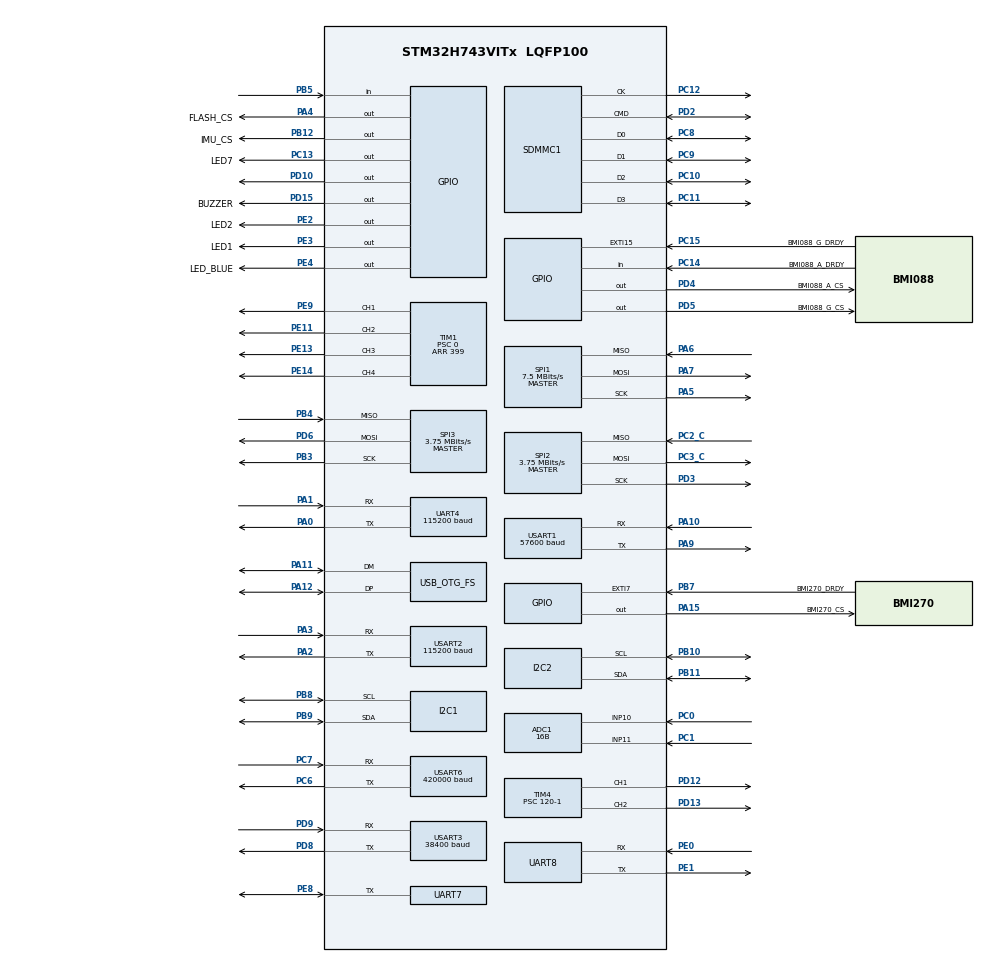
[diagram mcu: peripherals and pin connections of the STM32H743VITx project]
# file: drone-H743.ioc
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ADC1.Channel-0\#ChannelRegularConversion=ADC_CHANNEL_11
ADC1.Channel-1\#ChannelRegularConversion=ADC_CHANNEL_10
ADC1.ClockPrescaler=ADC_CLOCK_ASYNC_DIV4
ADC1.ContinuousConvMode=DISABLE
ADC1.ConversionDataManagement=ADC_CONVERSIONDATA_DR
ADC1.DiscontinuousConvMode=ENABLE
ADC1.EOCSelection=ADC_EOC_SINGLE_CONV
ADC1.ExternalTrigConv=ADC_SOFTWARE_START
ADC1.ExternalTrigConvEdge=ADC_EXTERNALTRIGCONVEDGE_NONE
ADC1.NbrOfConversion=2
ADC1.NbrOfConversionFlag=1
ADC1.NbrOfDiscConversion=1
ADC1.OffsetNumber-0\#ChannelRegularConversion=ADC_OFFSET_NONE
ADC1.OffsetNumber-1\#ChannelRegularConversion=ADC_OFFSET_NONE
ADC1.OffsetSignedSaturation-0\#ChannelRegularConversion=DISABLE
ADC1.OffsetSignedSaturation-1\#ChannelRegularConversion=DISABLE
ADC1.Overrun=ADC_OVR_DATA_PRESERVED
ADC1.Rank-0\#ChannelRegularConversion=1
ADC1.Rank-1\#ChannelRegularConversion=2
ADC1.Resolution=ADC_RESOLUTION_16B
ADC1.SamplingTime-0\#ChannelRegularConversion=ADC_SAMPLETIME_387CYCLES_5
ADC1.SamplingTime-1\#ChannelRegularConversion=ADC_SAMPLETIME_387CYCLES_5
ADC1.ScanConvMode=ADC_SCAN_ENABLE
ADC1.master=1
CORTEX_M7.CPU_DCache=Enabled
CORTEX_M7.CPU_ICache=Enabled
CORTEX_M7.default_mode_Activation=1
Dma.Request0=USART1_RX
Dma.Request1=USART1_TX
Dma.Request10=USART6_RX
Dma.Request11=USART6_TX
Dma.Request12=UART7_TX
Dma.Request13=UART7_RX
Dma.Request14=USART3_RX
Dma.Request15=USART3_TX
Dma.Request2=TIM1_UP
Dma.Request3=UART8_TX
Dma.Request4=UART4_RX
Dma.Request5=UART4_TX
Dma.Request6=SPI2_RX
Dma.Request7=SPI2_TX
Dma.Request8=SPI1_RX
Dma.Request9=SPI1_TX
Dma.SPI1_RX.8.Direction=DMA_PERIPH_TO_MEMORY
Dma.SPI1_RX.8.EventEnable=DISABLE
Dma.SPI1_RX.8.FIFOMode=DMA_FIFOMODE_DISABLE
Dma.SPI1_RX.8.Instance=DMA2_Stream0
Dma.SPI1_RX.8.MemDataAlignment=DMA_MDATAALIGN_BYTE
Dma.SPI1_RX.8.MemInc=DMA_MINC_ENABLE
Dma.SPI1_RX.8.Mode=DMA_NORMAL
Dma.SPI1_RX.8.PeriphDataAlignment=DMA_PDATAALIGN_BYTE
Dma.SPI1_RX.8.PeriphInc=DMA_PINC_DISABLE
Dma.SPI1_RX.8.Polarity=HAL_DMAMUX_REQ_GEN_RISING
Dma.SPI1_RX.8.Priority=DMA_PRIORITY_HIGH
Dma.SPI1_RX.8.RequestNumber=1
Dma.SPI1_RX.8.SignalID=NONE
Dma.SPI1_RX.8.SyncEnable=DISABLE
Dma.SPI1_RX.8.SyncPolarity=HAL_DMAMUX_SYNC_NO_EVENT
Dma.SPI1_RX.8.SyncRequestNumber=1
Dma.SPI1_RX.8.SyncSignalID=NONE
Dma.SPI1_TX.9.Direction=DMA_MEMORY_TO_PERIPH
Dma.SPI1_TX.9.EventEnable=DISABLE
Dma.SPI1_TX.9.FIFOMode=DMA_FIFOMODE_DISABLE
Dma.SPI1_TX.9.Instance=DMA2_Stream1
Dma.SPI1_TX.9.MemDataAlignment=DMA_MDATAALIGN_BYTE
Dma.SPI1_TX.9.MemInc=DMA_MINC_ENABLE
Dma.SPI1_TX.9.Mode=DMA_NORMAL
Dma.SPI1_TX.9.PeriphDataAlignment=DMA_PDATAALIGN_BYTE
Dma.SPI1_TX.9.PeriphInc=DMA_PINC_DISABLE
Dma.SPI1_TX.9.Polarity=HAL_DMAMUX_REQ_GEN_RISING
Dma.SPI1_TX.9.Priority=DMA_PRIORITY_HIGH
Dma.SPI1_TX.9.RequestNumber=1
Dma.SPI1_TX.9.SignalID=NONE
Dma.SPI1_TX.9.SyncEnable=DISABLE
Dma.SPI1_TX.9.SyncPolarity=HAL_DMAMUX_SYNC_NO_EVENT
Dma.SPI1_TX.9.SyncRequestNumber=1
Dma.SPI1_TX.9.SyncSignalID=NONE
Dma.SPI2_RX.6.Direction=DMA_PERIPH_TO_MEMORY
Dma.SPI2_RX.6.EventEnable=DISABLE
Dma.SPI2_RX.6.FIFOMode=DMA_FIFOMODE_DISABLE
Dma.SPI2_RX.6.Instance=DMA1_Stream6
Dma.SPI2_RX.6.MemDataAlignment=DMA_MDATAALIGN_BYTE
Dma.SPI2_RX.6.MemInc=DMA_MINC_ENABLE
Dma.SPI2_RX.6.Mode=DMA_NORMAL
Dma.SPI2_RX.6.PeriphDataAlignment=DMA_PDATAALIGN_BYTE
Dma.SPI2_RX.6.PeriphInc=DMA_PINC_DISABLE
Dma.SPI2_RX.6.Polarity=HAL_DMAMUX_REQ_GEN_RISING
Dma.SPI2_RX.6.Priority=DMA_PRIORITY_VERY_HIGH
Dma.SPI2_RX.6.RequestNumber=1
Dma.SPI2_RX.6.SignalID=NONE
Dma.SPI2_RX.6.SyncEnable=DISABLE
Dma.SPI2_RX.6.SyncPolarity=HAL_DMAMUX_SYNC_NO_EVENT
Dma.SPI2_RX.6.SyncRequestNumber=1
Dma.SPI2_RX.6.SyncSignalID=NONE
Dma.SPI2_TX.7.Direction=DMA_MEMORY_TO_PERIPH
Dma.SPI2_TX.7.EventEnable=DISABLE
Dma.SPI2_TX.7.FIFOMode=DMA_FIFOMODE_DISABLE
Dma.SPI2_TX.7.Instance=DMA1_Stream7
Dma.SPI2_TX.7.MemDataAlignment=DMA_MDATAALIGN_BYTE
Dma.SPI2_TX.7.MemInc=DMA_MINC_ENABLE
Dma.SPI2_TX.7.Mode=DMA_NORMAL
Dma.SPI2_TX.7.PeriphDataAlignment=DMA_PDATAALIGN_BYTE
Dma.SPI2_TX.7.PeriphInc=DMA_PINC_DISABLE
Dma.SPI2_TX.7.Polarity=HAL_DMAMUX_REQ_GEN_RISING
Dma.SPI2_TX.7.Priority=DMA_PRIORITY_VERY_HIGH
Dma.SPI2_TX.7.RequestNumber=1
Dma.SPI2_TX.7.SignalID=NONE
Dma.SPI2_TX.7.SyncEnable=DISABLE
Dma.SPI2_TX.7.SyncPolarity=HAL_DMAMUX_SYNC_NO_EVENT
Dma.SPI2_TX.7.SyncRequestNumber=1
Dma.SPI2_TX.7.SyncSignalID=NONE
Dma.TIM1_UP.2.Direction=DMA_MEMORY_TO_PERIPH
Dma.TIM1_UP.2.EventEnable=DISABLE
Dma.TIM1_UP.2.FIFOMode=DMA_FIFOMODE_DISABLE
Dma.TIM1_UP.2.Instance=DMA1_Stream2
Dma.TIM1_UP.2.MemDataAlignment=DMA_MDATAALIGN_WORD
Dma.TIM1_UP.2.MemInc=DMA_MINC_ENABLE
Dma.TIM1_UP.2.Mode=DMA_NORMAL
Dma.TIM1_UP.2.PeriphDataAlignment=DMA_PDATAALIGN_WORD
Dma.TIM1_UP.2.PeriphInc=DMA_PINC_DISABLE
Dma.TIM1_UP.2.Polarity=HAL_DMAMUX_REQ_GEN_RISING
Dma.TIM1_UP.2.Priority=DMA_PRIORITY_HIGH
Dma.TIM1_UP.2.RequestNumber=1
Dma.TIM1_UP.2.SignalID=NONE
Dma.TIM1_UP.2.SyncEnable=DISABLE
Dma.TIM1_UP.2.SyncPolarity=HAL_DMAMUX_SYNC_NO_EVENT
Dma.TIM1_UP.2.SyncRequestNumber=1
Dma.TIM1_UP.2.SyncSignalID=NONE
Dma.UART4_RX.4.Direction=DMA_PERIPH_TO_MEMORY
Dma.UART4_RX.4.EventEnable=DISABLE
Dma.UART4_RX.4.FIFOMode=DMA_FIFOMODE_DISABLE
Dma.UART4_RX.4.Instance=DMA1_Stream4
Dma.UART4_RX.4.MemDataAlignment=DMA_MDATAALIGN_BYTE
Dma.UART4_RX.4.MemInc=DMA_MINC_ENABLE
Dma.UART4_RX.4.Mode=DMA_CIRCULAR
Dma.UART4_RX.4.PeriphDataAlignment=DMA_PDATAALIGN_BYTE
Dma.UART4_RX.4.PeriphInc=DMA_PINC_DISABLE
Dma.UART4_RX.4.Polarity=HAL_DMAMUX_REQ_GEN_RISING
Dma.UART4_RX.4.Priority=DMA_PRIORITY_HIGH
Dma.UART4_RX.4.RequestNumber=1
Dma.UART4_RX.4.SignalID=NONE
Dma.UART4_RX.4.SyncEnable=DISABLE
Dma.UART4_RX.4.SyncPolarity=HAL_DMAMUX_SYNC_NO_EVENT
Dma.UART4_RX.4.SyncRequestNumber=1
Dma.UART4_RX.4.SyncSignalID=NONE
Dma.UART4_TX.5.Direction=DMA_MEMORY_TO_PERIPH
Dma.UART4_TX.5.EventEnable=DISABLE
Dma.UART4_TX.5.FIFOMode=DMA_FIFOMODE_DISABLE
Dma.UART4_TX.5.Instance=DMA1_Stream5
Dma.UART4_TX.5.MemDataAlignment=DMA_MDATAALIGN_BYTE
Dma.UART4_TX.5.MemInc=DMA_MINC_ENABLE
Dma.UART4_TX.5.Mode=DMA_NORMAL
Dma.UART4_TX.5.PeriphDataAlignment=DMA_PDATAALIGN_BYTE
Dma.UART4_TX.5.PeriphInc=DMA_PINC_DISABLE
Dma.UART4_TX.5.Polarity=HAL_DMAMUX_REQ_GEN_RISING
Dma.UART4_TX.5.Priority=DMA_PRIORITY_HIGH
Dma.UART4_TX.5.RequestNumber=1
Dma.UART4_TX.5.SignalID=NONE
Dma.UART4_TX.5.SyncEnable=DISABLE
Dma.UART4_TX.5.SyncPolarity=HAL_DMAMUX_SYNC_NO_EVENT
Dma.UART4_TX.5.SyncRequestNumber=1
Dma.UART4_TX.5.SyncSignalID=NONE
Dma.UART7_RX.13.Direction=DMA_PERIPH_TO_MEMORY
Dma.UART7_RX.13.EventEnable=DISABLE
Dma.UART7_RX.13.FIFOMode=DMA_FIFOMODE_DISABLE
Dma.UART7_RX.13.Instance=DMA2_Stream5
Dma.UART7_RX.13.MemDataAlignment=DMA_MDATAALIGN_BYTE
Dma.UART7_RX.13.MemInc=DMA_MINC_ENABLE
Dma.UART7_RX.13.Mode=DMA_NORMAL
Dma.UART7_RX.13.PeriphDataAlignment=DMA_PDATAALIGN_BYTE
Dma.UART7_RX.13.PeriphInc=DMA_PINC_DISABLE
Dma.UART7_RX.13.Polarity=HAL_DMAMUX_REQ_GEN_RISING
Dma.UART7_RX.13.Priority=DMA_PRIORITY_VERY_HIGH
Dma.UART7_RX.13.RequestNumber=1
Dma.UART7_RX.13.SignalID=NONE
Dma.UART7_RX.13.SyncEnable=DISABLE
Dma.UART7_RX.13.SyncPolarity=HAL_DMAMUX_SYNC_NO_EVENT
Dma.UART7_RX.13.SyncRequestNumber=1
Dma.UART7_RX.13.SyncSignalID=NONE
Dma.UART7_TX.12.Direction=DMA_MEMORY_TO_PERIPH
Dma.UART7_TX.12.EventEnable=DISABLE
Dma.UART7_TX.12.FIFOMode=DMA_FIFOMODE_DISABLE
Dma.UART7_TX.12.Instance=DMA2_Stream4
Dma.UART7_TX.12.MemDataAlignment=DMA_MDATAALIGN_BYTE
Dma.UART7_TX.12.MemInc=DMA_MINC_ENABLE
Dma.UART7_TX.12.Mode=DMA_NORMAL
Dma.UART7_TX.12.PeriphDataAlignment=DMA_PDATAALIGN_BYTE
Dma.UART7_TX.12.PeriphInc=DMA_PINC_DISABLE
Dma.UART7_TX.12.Polarity=HAL_DMAMUX_REQ_GEN_RISING
Dma.UART7_TX.12.Priority=DMA_PRIORITY_VERY_HIGH
Dma.UART7_TX.12.RequestNumber=1
Dma.UART7_TX.12.SignalID=NONE
Dma.UART7_TX.12.SyncEnable=DISABLE
Dma.UART7_TX.12.SyncPolarity=HAL_DMAMUX_SYNC_NO_EVENT
Dma.UART7_TX.12.SyncRequestNumber=1
Dma.UART7_TX.12.SyncSignalID=NONE
Dma.UART8_TX.3.Direction=DMA_MEMORY_TO_PERIPH
Dma.UART8_TX.3.EventEnable=DISABLE
Dma.UART8_TX.3.FIFOMode=DMA_FIFOMODE_DISABLE
Dma.UART8_TX.3.Instance=DMA1_Stream3
Dma.UART8_TX.3.MemDataAlignment=DMA_MDATAALIGN_BYTE
Dma.UART8_TX.3.MemInc=DMA_MINC_ENABLE
Dma.UART8_TX.3.Mode=DMA_NORMAL
Dma.UART8_TX.3.PeriphDataAlignment=DMA_PDATAALIGN_BYTE
Dma.UART8_TX.3.PeriphInc=DMA_PINC_DISABLE
Dma.UART8_TX.3.Polarity=HAL_DMAMUX_REQ_GEN_RISING
Dma.UART8_TX.3.Priority=DMA_PRIORITY_LOW
Dma.UART8_TX.3.RequestNumber=1
Dma.UART8_TX.3.SignalID=NONE
Dma.UART8_TX.3.SyncEnable=DISABLE
Dma.UART8_TX.3.SyncPolarity=HAL_DMAMUX_SYNC_NO_EVENT
Dma.UART8_TX.3.SyncRequestNumber=1
Dma.UART8_TX.3.SyncSignalID=NONE
Dma.USART1_RX.0.Direction=DMA_PERIPH_TO_MEMORY
Dma.USART1_RX.0.EventEnable=DISABLE
Dma.USART1_RX.0.FIFOMode=DMA_FIFOMODE_DISABLE
Dma.USART1_RX.0.Instance=DMA1_Stream0
Dma.USART1_RX.0.MemDataAlignment=DMA_MDATAALIGN_BYTE
Dma.USART1_RX.0.MemInc=DMA_MINC_ENABLE
Dma.USART1_RX.0.Mode=DMA_CIRCULAR
Dma.USART1_RX.0.PeriphDataAlignment=DMA_PDATAALIGN_BYTE
Dma.USART1_RX.0.PeriphInc=DMA_PINC_DISABLE
Dma.USART1_RX.0.Polarity=HAL_DMAMUX_REQ_GEN_RISING
Dma.USART1_RX.0.Priority=DMA_PRIORITY_LOW
Dma.USART1_RX.0.RequestNumber=1
Dma.USART1_RX.0.SignalID=NONE
Dma.USART1_RX.0.SyncEnable=DISABLE
Dma.USART1_RX.0.SyncPolarity=HAL_DMAMUX_SYNC_NO_EVENT
Dma.USART1_RX.0.SyncRequestNumber=1
Dma.USART1_RX.0.SyncSignalID=NONE
Dma.USART1_TX.1.Direction=DMA_MEMORY_TO_PERIPH
Dma.USART1_TX.1.EventEnable=DISABLE
Dma.USART1_TX.1.FIFOMode=DMA_FIFOMODE_DISABLE
Dma.USART1_TX.1.Instance=DMA1_Stream1
Dma.USART1_TX.1.MemDataAlignment=DMA_MDATAALIGN_BYTE
Dma.USART1_TX.1.MemInc=DMA_MINC_ENABLE
Dma.USART1_TX.1.Mode=DMA_NORMAL
Dma.USART1_TX.1.PeriphDataAlignment=DMA_PDATAALIGN_BYTE
Dma.USART1_TX.1.PeriphInc=DMA_PINC_DISABLE
Dma.USART1_TX.1.Polarity=HAL_DMAMUX_REQ_GEN_RISING
Dma.USART1_TX.1.Priority=DMA_PRIORITY_LOW
Dma.USART1_TX.1.RequestNumber=1
Dma.USART1_TX.1.SignalID=NONE
Dma.USART1_TX.1.SyncEnable=DISABLE
Dma.USART1_TX.1.SyncPolarity=HAL_DMAMUX_SYNC_NO_EVENT
Dma.USART1_TX.1.SyncRequestNumber=1
Dma.USART1_TX.1.SyncSignalID=NONE
Dma.USART3_RX.14.Direction=DMA_PERIPH_TO_MEMORY
Dma.USART3_RX.14.EventEnable=DISABLE
Dma.USART3_RX.14.FIFOMode=DMA_FIFOMODE_DISABLE
Dma.USART3_RX.14.Instance=DMA2_Stream6
Dma.USART3_RX.14.MemDataAlignment=DMA_MDATAALIGN_BYTE
Dma.USART3_RX.14.MemInc=DMA_MINC_ENABLE
Dma.USART3_RX.14.Mode=DMA_CIRCULAR
Dma.USART3_RX.14.PeriphDataAlignment=DMA_PDATAALIGN_BYTE
Dma.USART3_RX.14.PeriphInc=DMA_PINC_DISABLE
Dma.USART3_RX.14.Polarity=HAL_DMAMUX_REQ_GEN_RISING
Dma.USART3_RX.14.Priority=DMA_PRIORITY_HIGH
Dma.USART3_RX.14.RequestNumber=1
Dma.USART3_RX.14.SignalID=NONE
Dma.USART3_RX.14.SyncEnable=DISABLE
Dma.USART3_RX.14.SyncPolarity=HAL_DMAMUX_SYNC_NO_EVENT
Dma.USART3_RX.14.SyncRequestNumber=1
Dma.USART3_RX.14.SyncSignalID=NONE
Dma.USART3_TX.15.Direction=DMA_MEMORY_TO_PERIPH
Dma.USART3_TX.15.EventEnable=DISABLE
Dma.USART3_TX.15.FIFOMode=DMA_FIFOMODE_DISABLE
Dma.USART3_TX.15.Instance=DMA2_Stream7
Dma.USART3_TX.15.MemDataAlignment=DMA_MDATAALIGN_BYTE
Dma.USART3_TX.15.MemInc=DMA_MINC_ENABLE
Dma.USART3_TX.15.Mode=DMA_NORMAL
Dma.USART3_TX.15.PeriphDataAlignment=DMA_PDATAALIGN_BYTE
Dma.USART3_TX.15.PeriphInc=DMA_PINC_DISABLE
Dma.USART3_TX.15.Polarity=HAL_DMAMUX_REQ_GEN_RISING
Dma.USART3_TX.15.Priority=DMA_PRIORITY_HIGH
Dma.USART3_TX.15.RequestNumber=1
Dma.USART3_TX.15.SignalID=NONE
Dma.USART3_TX.15.SyncEnable=DISABLE
Dma.USART3_TX.15.SyncPolarity=HAL_DMAMUX_SYNC_NO_EVENT
Dma.USART3_TX.15.SyncRequestNumber=1
Dma.USART3_TX.15.SyncSignalID=NONE
Dma.USART6_RX.10.Direction=DMA_PERIPH_TO_MEMORY
Dma.USART6_RX.10.EventEnable=DISABLE
Dma.USART6_RX.10.FIFOMode=DMA_FIFOMODE_DISABLE
Dma.USART6_RX.10.Instance=DMA2_Stream2
Dma.USART6_RX.10.MemDataAlignment=DMA_MDATAALIGN_BYTE
Dma.USART6_RX.10.MemInc=DMA_MINC_ENABLE
Dma.USART6_RX.10.Mode=DMA_CIRCULAR
Dma.USART6_RX.10.PeriphDataAlignment=DMA_PDATAALIGN_BYTE
Dma.USART6_RX.10.PeriphInc=DMA_PINC_DISABLE
Dma.USART6_RX.10.Polarity=HAL_DMAMUX_REQ_GEN_RISING
Dma.USART6_RX.10.Priority=DMA_PRIORITY_LOW
Dma.USART6_RX.10.RequestNumber=1
Dma.USART6_RX.10.SignalID=NONE
Dma.USART6_RX.10.SyncEnable=DISABLE
Dma.USART6_RX.10.SyncPolarity=HAL_DMAMUX_SYNC_NO_EVENT
Dma.USART6_RX.10.SyncRequestNumber=1
Dma.USART6_RX.10.SyncSignalID=NONE
Dma.USART6_TX.11.Direction=DMA_MEMORY_TO_PERIPH
Dma.USART6_TX.11.EventEnable=DISABLE
Dma.USART6_TX.11.FIFOMode=DMA_FIFOMODE_DISABLE
Dma.USART6_TX.11.Instance=DMA2_Stream3
Dma.USART6_TX.11.MemDataAlignment=DMA_MDATAALIGN_BYTE
Dma.USART6_TX.11.MemInc=DMA_MINC_ENABLE
Dma.USART6_TX.11.Mode=DMA_NORMAL
Dma.USART6_TX.11.PeriphDataAlignment=DMA_PDATAALIGN_BYTE
Dma.USART6_TX.11.PeriphInc=DMA_PINC_DISABLE
Dma.USART6_TX.11.Polarity=HAL_DMAMUX_REQ_GEN_RISING
Dma.USART6_TX.11.Priority=DMA_PRIORITY_LOW
Dma.USART6_TX.11.RequestNumber=1
Dma.USART6_TX.11.SignalID=NONE
Dma.USART6_TX.11.SyncEnable=DISABLE
Dma.USART6_TX.11.SyncPolarity=HAL_DMAMUX_SYNC_NO_EVENT
Dma.USART6_TX.11.SyncRequestNumber=1
Dma.USART6_TX.11.SyncSignalID=NONE
FREERTOS.Queues01=uartTxQueue,32,APP_UART_TxMessage,0,Dynamic,NULL,NULL;SensorSampleQueue,8,APP_Sensor_SampleMessage,0,Dynamic,NULL,NULL;backgroundReqQueue,8,APP_BackgroundRequest,0,Dynamic,NULL,NULL;backgroundRespQueue,8,APP_BackgroundResponse,0,Dynamic,NULL,NULL;vofaLogQueue,1,APP_Sensor_SampleMessage,0,Dynamic,NULL,NULL
FREERTOS.RecursiveMutexes01=flashBusMutex,Dynamic,NULL
FREERTOS.Tasks01=Stabilizer,24,2048,StabilizerTask,Default,NULL,Dynamic,NULL,NULL;SensorTask,24,512,Sensor_Task,Default,NULL,Dynamic,NULL,NULL;messageTask,16,1024,message_push,Default,NULL,Dynamic,NULL,NULL;UARTTask,24,1024,UART_fun,Default,NULL,Dynamic,NULL,NULL;backgroundTask,16,1024,BackgroundTask,Default,NULL,Dynamic,NULL,NULL;VOFA_Task,16,512,VOFA_task,Default,NULL,Dynamic,NULL,NULL
FREERTOS.configCHECK_FOR_STACK_OVERFLOW=2
FREERTOS.configENABLE_FPU=1
FREERTOS.configMINIMAL_STACK_SIZE=512
FREERTOS.configTOTAL_HEAP_SIZE=65536
FREERTOS.configUSE_MALLOC_FAILED_HOOK=1
FREERTOS.configUSE_MUTEXES=1
FREERTOS.configUSE_RECURSIVE_MUTEXES=1
I2C1.Timing=0x107075B0
I2C2.Timing=0x107075B0
Mcu.Family=STM32H7
Mcu.Name=STM32H743VITx
Mcu.Package=LQFP100
NVIC.DMA1_Stream0_IRQn=true\:5\:0\:false\:false\:true\:true\:false\:true\:true
NVIC.DMA1_Stream1_IRQn=true\:5\:0\:false\:false\:true\:true\:false\:true\:true
NVIC.DMA1_Stream2_IRQn=true\:5\:0\:false\:false\:true\:true\:false\:true\:true
NVIC.DMA1_Stream3_IRQn=true\:5\:0\:false\:false\:true\:true\:false\:true\:true
NVIC.DMA1_Stream4_IRQn=true\:5\:0\:false\:false\:true\:true\:false\:true\:true
NVIC.DMA1_Stream5_IRQn=true\:5\:0\:false\:false\:true\:true\:false\:true\:true
NVIC.DMA1_Stream6_IRQn=true\:5\:0\:false\:false\:true\:true\:false\:true\:true
NVIC.DMA1_Stream7_IRQn=true\:5\:0\:false\:false\:true\:true\:false\:true\:true
NVIC.DMA2_Stream0_IRQn=true\:5\:0\:false\:false\:true\:true\:false\:true\:true
NVIC.DMA2_Stream1_IRQn=true\:5\:0\:false\:false\:true\:true\:false\:true\:true
NVIC.DMA2_Stream2_IRQn=true\:5\:0\:false\:false\:true\:true\:false\:true\:true
NVIC.DMA2_Stream3_IRQn=true\:5\:0\:false\:false\:true\:true\:false\:true\:true
NVIC.DMA2_Stream4_IRQn=true\:5\:0\:false\:false\:true\:true\:false\:true\:true
NVIC.DMA2_Stream5_IRQn=true\:5\:0\:false\:false\:true\:true\:false\:true\:true
NVIC.DMA2_Stream6_IRQn=true\:5\:0\:false\:false\:true\:true\:false\:true\:true
NVIC.DMA2_Stream7_IRQn=true\:5\:0\:false\:false\:true\:true\:false\:true\:true
NVIC.EXTI15_10_IRQn=true\:5\:0\:true\:false\:true\:true\:true\:true\:true
NVIC.EXTI9_5_IRQn=true\:5\:0\:true\:false\:true\:true\:true\:true\:true
NVIC.OTG_FS_IRQn=true\:5\:0\:false\:false\:true\:true\:false\:true\:true
NVIC.PriorityGroup=NVIC_PRIORITYGROUP_4
NVIC.SDMMC1_IRQn=true\:5\:0\:false\:false\:true\:true\:true\:true\:true
NVIC.SPI1_IRQn=true\:5\:0\:false\:false\:true\:true\:false\:true\:true
NVIC.SPI2_IRQn=true\:5\:0\:false\:false\:true\:true\:false\:true\:true
NVIC.TIM17_IRQn=true\:5\:0\:false\:false\:true\:true\:true\:true\:true
NVIC.TIM3_IRQn=true\:15\:0\:false\:false\:true\:false\:false\:true\:true
NVIC.TimeBase=TIM3_IRQn
NVIC.TimeBaseIP=TIM3
NVIC.UART4_IRQn=true\:5\:0\:false\:false\:true\:true\:true\:true\:true
NVIC.UART7_IRQn=true\:5\:0\:false\:false\:true\:true\:true\:true\:true
NVIC.UART8_IRQn=true\:5\:0\:false\:false\:true\:true\:true\:true\:true
NVIC.USART1_IRQn=true\:5\:0\:false\:false\:true\:true\:true\:true\:true
NVIC.USART2_IRQn=true\:5\:0\:false\:false\:true\:true\:true\:true\:true
NVIC.USART3_IRQn=true\:5\:0\:false\:false\:true\:true\:true\:true\:true
NVIC.USART6_IRQn=true\:5\:0\:false\:false\:true\:true\:true\:true\:true
PA0.Mode=Asynchronous
PA0.Signal=UART4_TX
PA1.Mode=Asynchronous
PA1.Signal=UART4_RX
PA10.Mode=Asynchronous
PA10.Signal=USART1_RX
PA11.Mode=Device_Only
PA11.Signal=USB_OTG_FS_DM
PA12.Mode=Device_Only
PA12.Signal=USB_OTG_FS_DP
PA13\ (JTMS/SWDIO).Mode=Serial_Wire
PA13\ (JTMS/SWDIO).Signal=DEBUG_JTMS-SWDIO
PA14\ (JTCK/SWCLK).Mode=Serial_Wire
PA14\ (JTCK/SWCLK).Signal=DEBUG_JTCK-SWCLK
PA15\ (JTDI).GPIO_Label=BMI270_CS
PA15\ (JTDI).GPIO_PuPd=GPIO_PULLUP
PA15\ (JTDI).GPIO_Speed=GPIO_SPEED_FREQ_VERY_HIGH
PA15\ (JTDI).PinState=GPIO_PIN_SET
PA15\ (JTDI).Signal=GPIO_Output
PA2.Mode=Asynchronous
PA2.Signal=USART2_TX
PA3.Mode=Asynchronous
PA3.Signal=USART2_RX
PA4.GPIO_Label=FLASH_CS
PA4.GPIO_PuPd=GPIO_PULLUP
PA4.GPIO_Speed=GPIO_SPEED_FREQ_VERY_HIGH
PA4.PinState=GPIO_PIN_SET
PA4.Signal=GPIO_Output
PA5.Mode=Full_Duplex_Master
PA5.Signal=SPI1_SCK
PA6.Mode=Full_Duplex_Master
PA6.Signal=SPI1_MISO
PA7.Mode=Full_Duplex_Master
PA7.Signal=SPI1_MOSI
PA9.Mode=Asynchronous
PA9.Signal=USART1_TX
PB10.Mode=I2C
PB10.Signal=I2C2_SCL
PB11.Mode=I2C
PB11.Signal=I2C2_SDA
PB12.GPIO_Label=IMU_CS
PB12.GPIO_PuPd=GPIO_PULLUP
PB12.GPIO_Speed=GPIO_SPEED_FREQ_HIGH
PB12.PinState=GPIO_PIN_SET
PB12.Signal=GPIO_Output
PB3\ (JTDO/TRACESWO).GPIO_Speed=GPIO_SPEED_FREQ_VERY_HIGH
PB3\ (JTDO/TRACESWO).Mode=Full_Duplex_Master
PB3\ (JTDO/TRACESWO).Signal=SPI3_SCK
PB4\ (NJTRST).Mode=Full_Duplex_Master
PB4\ (NJTRST).Signal=SPI3_MISO
PB5.Signal=GPIO_Input
PB7.GPIO_Label=BMI270_DRDY
PB7.Signal=GPXTI7
PB8.Mode=I2C
PB8.Signal=I2C1_SCL
PB9.Mode=I2C
PB9.Signal=I2C1_SDA
PC0.Signal=ADCx_INP10
PC1.Signal=ADCx_INP11
PC10.GPIO_PuPd=GPIO_PULLUP
PC10.Mode=SD_4_bits_Wide_bus
PC10.Signal=SDMMC1_D2
PC11.GPIO_PuPd=GPIO_PULLUP
PC11.Mode=SD_4_bits_Wide_bus
PC11.Signal=SDMMC1_D3
PC12.Mode=SD_4_bits_Wide_bus
PC12.Signal=SDMMC1_CK
PC13.GPIO_Label=LED7
PC13.GPIO_PuPd=GPIO_PULLUP
PC13.PinState=GPIO_PIN_SET
PC13.Signal=GPIO_Output
PC14-OSC32_IN\ (OSC32_IN).GPIO_Label=BMI088_A_DRDY
PC14-OSC32_IN\ (OSC32_IN).Signal=GPIO_Input
PC15-OSC32_OUT\ (OSC32_OUT).GPIO_Label=BMI088_G_DRDY
PC15-OSC32_OUT\ (OSC32_OUT).Signal=GPXTI15
PC2_C.Mode=Full_Duplex_Master
PC2_C.Signal=SPI2_MISO
PC3_C.GPIO_Speed=GPIO_SPEED_FREQ_VERY_HIGH
PC3_C.Mode=Full_Duplex_Master
PC3_C.Signal=SPI2_MOSI
PC6.Mode=Asynchronous
PC6.Signal=USART6_TX
PC7.Mode=Asynchronous
PC7.Signal=USART6_RX
PC8.GPIO_PuPd=GPIO_PULLUP
PC8.Mode=SD_4_bits_Wide_bus
PC8.Signal=SDMMC1_D0
PC9.GPIO_PuPd=GPIO_PULLUP
PC9.Mode=SD_4_bits_Wide_bus
PC9.Signal=SDMMC1_D1
PD10.Signal=GPIO_Output
PD12.Signal=S_TIM4_CH1
PD13.Signal=S_TIM4_CH2
PD15.GPIO_Label=BUZZER
PD15.PinState=GPIO_PIN_RESET
PD15.Signal=GPIO_Output
PD2.GPIO_PuPd=GPIO_PULLUP
PD2.Mode=SD_4_bits_Wide_bus
PD2.Signal=SDMMC1_CMD
PD3.GPIO_Speed=GPIO_SPEED_FREQ_VERY_HIGH
PD3.Mode=Full_Duplex_Master
PD3.Signal=SPI2_SCK
PD4.GPIO_Label=BMI088_A_CS
PD4.GPIO_PuPd=GPIO_PULLUP
PD4.GPIO_Speed=GPIO_SPEED_FREQ_VERY_HIGH
PD4.PinState=GPIO_PIN_SET
PD4.Signal=GPIO_Output
PD5.GPIO_Label=BMI088_G_CS
PD5.GPIO_PuPd=GPIO_PULLUP
PD5.GPIO_Speed=GPIO_SPEED_FREQ_VERY_HIGH
PD5.PinState=GPIO_PIN_SET
PD5.Signal=GPIO_Output
PD6.GPIO_Speed=GPIO_SPEED_FREQ_VERY_HIGH
PD6.Mode=Full_Duplex_Master
PD6.Signal=SPI3_MOSI
PD8.Mode=Asynchronous
PD8.Signal=USART3_TX
PD9.Mode=Asynchronous
PD9.Signal=USART3_RX
PE0.Mode=Asynchronous
PE0.Signal=UART8_RX
PE1.Mode=Asynchronous
PE1.Signal=UART8_TX
PE11.GPIO_Speed=GPIO_SPEED_FREQ_VERY_HIGH
PE11.Signal=S_TIM1_CH2
PE13.Signal=S_TIM1_CH3
PE14.Signal=S_TIM1_CH4
PE2.GPIO_Label=LED2
PE2.PinState=GPIO_PIN_RESET
PE2.Signal=GPIO_Output
PE3.GPIO_Label=LED1
PE3.PinState=GPIO_PIN_RESET
PE3.Signal=GPIO_Output
PE4.GPIO_Label=LED_BLUE
PE4.PinState=GPIO_PIN_RESET
PE4.Signal=GPIO_Output
PE8.GPIO_PuPd=GPIO_PULLUP
PE8.Mode=Half_duplex(single_wire_mode)
PE8.Signal=UART7_TX
PE9.GPIO_Speed=GPIO_SPEED_FREQ_VERY_HIGH
PE9.Signal=S_TIM1_CH1
PH0-OSC_IN\ (PH0).Mode=HSE-External-Oscillator
PH0-OSC_IN\ (PH0).Signal=RCC_OSC_IN
PH1-OSC_OUT\ (PH1).Mode=HSE-External-Oscillator
PH1-OSC_OUT\ (PH1).Signal=RCC_OSC_OUT
ProjectManager.HeapSize=0x200
ProjectManager.StackSize=0x400
ProjectManager.TargetToolchain=CMake
RCC.ADCFreq_Value=32000000
RCC.APB1Freq_Value=60000000
RCC.APB2Freq_Value=60000000
RCC.APB3Freq_Value=120000000
RCC.APB4Freq_Value=60000000
RCC.CortexFreq_Value=240000000
RCC.D2PPRE1=RCC_APB1_DIV2
RCC.D2PPRE2=RCC_APB2_DIV2
RCC.D3PPRE=RCC_APB4_DIV2
RCC.DIVM1=1
RCC.DIVM2=4
RCC.DIVM3=1
RCC.DIVN1=60
RCC.DIVN2=128
RCC.DIVN3=24
RCC.DIVP2=8
RCC.DIVQ1=4
RCC.DIVQ2=8
RCC.DIVQ3=4
RCC.DIVR2=8
RCC.DIVR3=1
RCC.HCLKFreq_Value=120000000
RCC.HPRE=RCC_HCLK_DIV2
RCC.HSE_VALUE=8000000
RCC.PLL2FRACN=0
RCC.PLL3FRACN=0
RCC.PLLFRACN=0
RCC.PLLSourceVirtual=RCC_PLLSOURCE_HSE
RCC.SYSCLKFreq_VALUE=240000000
RCC.SYSCLKSource=RCC_SYSCLKSOURCE_PLLCLK
RCC.USBCLockSelection=RCC_USBCLKSOURCE_PLL3
RCC.USBFreq_Value=48000000
SDMMC1.ClockDiv=4
SDMMC1.HardwareFlowControl=SDMMC_HARDWARE_FLOW_CONTROL_ENABLE
SH.ADCx_INP10.0=ADC1_INP10,IN10-Single-Ended
SH.ADCx_INP11.0=ADC1_INP11,IN11-Single-Ended
SH.S_TIM1_CH1.0=TIM1_CH1,PWM Generation1 CH1
SH.S_TIM1_CH2.0=TIM1_CH2,PWM Generation2 CH2
SH.S_TIM1_CH3.0=TIM1_CH3,PWM Generation3 CH3
SH.S_TIM1_CH4.0=TIM1_CH4,PWM Generation4 CH4
SH.S_TIM4_CH1.0=TIM4_CH1,PWM Generation1 CH1
SH.S_TIM4_CH2.0=TIM4_CH2,PWM Generation2 CH2
SPI1.BaudRatePrescaler=SPI_BAUDRATEPRESCALER_16
SPI1.CalculateBaudRate=7.5 MBits/s
SPI1.DataSize=SPI_DATASIZE_8BIT
SPI1.Direction=SPI_DIRECTION_2LINES
SPI1.MasterKeepIOState=SPI_MASTER_KEEP_IO_STATE_ENABLE
SPI1.Mode=SPI_MODE_MASTER
SPI1.NSSPMode=SPI_NSS_PULSE_ENABLE
SPI1.VirtualType=VM_MASTER
SPI2.BaudRatePrescaler=SPI_BAUDRATEPRESCALER_32
SPI2.CalculateBaudRate=3.75 MBits/s
SPI2.DataSize=SPI_DATASIZE_8BIT
SPI2.Direction=SPI_DIRECTION_2LINES
SPI2.MasterKeepIOState=SPI_MASTER_KEEP_IO_STATE_ENABLE
SPI2.Mode=SPI_MODE_MASTER
SPI2.VirtualNSS=VM_NSSHARD
SPI2.VirtualType=VM_MASTER
SPI3.BaudRatePrescaler=SPI_BAUDRATEPRESCALER_32
SPI3.CalculateBaudRate=3.75 MBits/s
SPI3.DataSize=SPI_DATASIZE_8BIT
SPI3.Direction=SPI_DIRECTION_2LINES
SPI3.MasterKeepIOState=SPI_MASTER_KEEP_IO_STATE_ENABLE
SPI3.Mode=SPI_MODE_MASTER
SPI3.VirtualNSS=VM_NSSHARD
SPI3.VirtualType=VM_MASTER
TIM1.AutoReloadPreload=TIM_AUTORELOAD_PRELOAD_ENABLE
TIM1.Channel-PWM\ Generation1\ CH1=TIM_CHANNEL_1
TIM1.Channel-PWM\ Generation2\ CH2=TIM_CHANNEL_2
TIM1.Channel-PWM\ Generation3\ CH3=TIM_CHANNEL_3
TIM1.Channel-PWM\ Generation4\ CH4=TIM_CHANNEL_4
TIM1.Period=399
TIM1.Prescaler=0
TIM17.AutoReloadPreload=TIM_AUTORELOAD_PRELOAD_ENABLE
TIM17.Prescaler=120-1
TIM4.Channel-PWM\ Generation1\ CH1=TIM_CHANNEL_1
TIM4.Channel-PWM\ Generation2\ CH2=TIM_CHANNEL_2
TIM4.Period=19999
TIM4.Prescaler=120-1
UART4.BaudRate=115200
USART1.BaudRate=57600
USART1.VirtualMode-Asynchronous=VM_ASYNC
USART2.BaudRate=115200
USART2.VirtualMode-Asynchronous=VM_ASYNC
USART3.BaudRate=38400
USART3.VirtualMode-Asynchronous=VM_ASYNC
USART6.BaudRate=420000
USART6.VirtualMode=VM_ASYNC
USART6.VirtualMode-Asynchronous=VM_ASYNC
USB_DEVICE.CLASS_NAME_FS=CDC
USB_DEVICE.VirtualMode-CDC_FS=Cdc
USB_DEVICE.VirtualModeFS=Cdc_FS
USB_OTG_FS.VirtualMode=Device_Only
VP_FREERTOS_VS_CMSIS_V2.Mode=CMSIS_V2
VP_MEMORYMAP_VS_MEMORYMAP.Mode=CurAppReg
VP_SYS_VS_tim3.Mode=TIM3
VP_TIM17_VS_ClockSourceINT.Mode=Enable_Timer
VP_TIM1_VS_ClockSourceINT.Mode=Internal
VP_TIM4_VS_ClockSourceINT.Mode=Internal
VP_USB_DEVICE_VS_USB_DEVICE_CDC_FS.Mode=CDC_FS
board=custom

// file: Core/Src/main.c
/* USER CODE BEGIN Header */
/**
  ******************************************************************************
  * @file           : main.c
  * @brief          : Main program body
  ******************************************************************************
  * @attention
  *
  * Copyright (c) 2026 STMicroelectronics.
  * All rights reserved.
  *
  * This software is licensed under terms that can be found in the LICENSE file
  * in the root directory of this software component.
  * If no LICENSE file comes with this software, it is provided AS-IS.
  *
  ******************************************************************************
  */
/* USER CODE END Header */
#include "main.h"
#include "FreeRTOS.h"
#include "cmsis_os2.h"
#include "adc.h"
#include "dma.h"
#include "i2c.h"
#include "sdmmc.h"
#include "spi.h"
#include "tim.h"
#include "usart.h"
#include "usb_device.h"
#include "gpio.h"

/* USER CODE BEGIN Includes */
#include "bsp.h"
#include "app.h"
#include "app_boot.h"
#include "svc_timestamp.h"
#include <string.h>
/* USER CODE END Includes */

/* USER CODE BEGIN PM */
#define MAIN_UART_BOOT_DIAG_ENABLED 0U
#define MAIN_IMU_SPI_WAVEFORM_ONLY  0U
#define MAIN_IMU_I2C_PROBE_ONLY     0U

/* USER CODE END PM */

void SystemClock_Config(void);
static void MPU_Config(void);
void MX_FREERTOS_Init(void);

/* USER CODE BEGIN 0 */
static void Main_StagePulse(uint32_t stage)
{
  if (osKernelGetState() != osKernelInactive)
  {
    return;
  }

  for (uint32_t i = 0; i < stage; ++i)
  {
    HAL_GPIO_TogglePin(LED1_GPIO_Port, LED1_Pin);
    HAL_Delay(80);
    HAL_GPIO_TogglePin(LED1_GPIO_Port, LED1_Pin);
    HAL_Delay(80);
  }

  HAL_Delay(220);
}

static void Main_DebugUartPrint(const char *text)
{
#if (BSP_UART_USART1_OUTPUT_ENABLED == 0U) || (MAIN_UART_BOOT_DIAG_ENABLED == 0U)
  (void)text;
  return;
#else
  if (text == NULL)
  {
    return;
  }

  (void)HAL_UART_Transmit(&huart1,
                          (uint8_t *)text,
                          (uint16_t)strlen(text),
                          100U);
#endif
}

#if MAIN_IMU_SPI_WAVEFORM_ONLY
static void Main_ImuWaveDelay(void)
{
  for (volatile uint32_t i = 0U; i < 8000U; ++i)
  {
    __NOP();
  }
}

static void Main_ImuWavePinsInit(void)
{
  GPIO_InitTypeDef GPIO_InitStruct = {0};

  __HAL_RCC_GPIOA_CLK_ENABLE();
  __HAL_RCC_GPIOB_CLK_ENABLE();
  __HAL_RCC_GPIOC_CLK_ENABLE();

  HAL_GPIO_WritePin(IMU_CS_GPIO_Port, IMU_CS_Pin, GPIO_PIN_SET);
  HAL_GPIO_WritePin(GPIOA, GPIO_PIN_9, GPIO_PIN_RESET);
  HAL_GPIO_WritePin(GPIOC, GPIO_PIN_1, GPIO_PIN_RESET);

  GPIO_InitStruct.Pin = IMU_CS_Pin;
  GPIO_InitStruct.Mode = GPIO_MODE_OUTPUT_PP;
  GPIO_InitStruct.Pull = GPIO_PULLUP;
  GPIO_InitStruct.Speed = GPIO_SPEED_FREQ_LOW;
  HAL_GPIO_Init(IMU_CS_GPIO_Port, &GPIO_InitStruct);

  GPIO_InitStruct.Pin = GPIO_PIN_9;
  GPIO_InitStruct.Mode = GPIO_MODE_OUTPUT_PP;
  GPIO_InitStruct.Pull = GPIO_NOPULL;
  GPIO_InitStruct.Speed = GPIO_SPEED_FREQ_LOW;
  HAL_GPIO_Init(GPIOA, &GPIO_InitStruct);

  GPIO_InitStruct.Pin = GPIO_PIN_1;
  GPIO_InitStruct.Mode = GPIO_MODE_OUTPUT_PP;
  GPIO_InitStruct.Pull = GPIO_NOPULL;
  GPIO_InitStruct.Speed = GPIO_SPEED_FREQ_LOW;
  HAL_GPIO_Init(GPIOC, &GPIO_InitStruct);

  GPIO_InitStruct.Pin = GPIO_PIN_2;
  GPIO_InitStruct.Mode = GPIO_MODE_INPUT;
  GPIO_InitStruct.Pull = GPIO_NOPULL;
  HAL_GPIO_Init(GPIOC, &GPIO_InitStruct);

  HAL_SYSCFG_AnalogSwitchConfig(SYSCFG_SWITCH_PC2, SYSCFG_SWITCH_PC2_CLOSE);
}

static void Main_ImuWaveByte(uint8_t value)
{
  for (uint8_t mask = 0x80U; mask != 0U; mask >>= 1U)
  {
    HAL_GPIO_WritePin(GPIOC, GPIO_PIN_1,
                      ((value & mask) != 0U) ? GPIO_PIN_SET : GPIO_PIN_RESET);
    Main_ImuWaveDelay();
    HAL_GPIO_WritePin(GPIOA, GPIO_PIN_9, GPIO_PIN_SET);
    Main_ImuWaveDelay();
    HAL_GPIO_WritePin(GPIOA, GPIO_PIN_9, GPIO_PIN_RESET);
    Main_ImuWaveDelay();
  }
}

static void Main_ImuWaveLoop(void)
{
  Main_ImuWavePinsInit();

  while (1)
  {
    HAL_GPIO_WritePin(IMU_CS_GPIO_Port, IMU_CS_Pin, GPIO_PIN_SET);
    HAL_GPIO_WritePin(GPIOA, GPIO_PIN_9, GPIO_PIN_RESET);
    HAL_GPIO_WritePin(GPIOC, GPIO_PIN_1, GPIO_PIN_RESET);
    HAL_Delay(5U);

    HAL_GPIO_WritePin(IMU_CS_GPIO_Port, IMU_CS_Pin, GPIO_PIN_RESET);
    Main_ImuWaveDelay();
    Main_ImuWaveByte(0xF5U);
    Main_ImuWaveByte(0x00U);
    Main_ImuWaveDelay();
    HAL_GPIO_WritePin(IMU_CS_GPIO_Port, IMU_CS_Pin, GPIO_PIN_SET);
  }
}
#endif

#if MAIN_IMU_I2C_PROBE_ONLY
#define MAIN_IMU_I2C_SCL_PORT GPIOA
#define MAIN_IMU_I2C_SCL_PIN  GPIO_PIN_9
#define MAIN_IMU_I2C_SDA_PORT GPIOC
#define MAIN_IMU_I2C_SDA_PIN  GPIO_PIN_1

static void Main_ImuI2cDelay(void)
{
  for (volatile uint32_t i = 0U; i < 1200U; ++i)
  {
    __NOP();
  }
}

static void Main_ImuI2cSetScl(uint8_t high)
{
  HAL_GPIO_WritePin(MAIN_IMU_I2C_SCL_PORT,
                    MAIN_IMU_I2C_SCL_PIN,
                    high != 0U ? GPIO_PIN_SET : GPIO_PIN_RESET);
}

static void Main_ImuI2cSetSda(uint8_t high)
{
  HAL_GPIO_WritePin(MAIN_IMU_I2C_SDA_PORT,
                    MAIN_IMU_I2C_SDA_PIN,
                    high != 0U ? GPIO_PIN_SET : GPIO_PIN_RESET);
}

static uint8_t Main_ImuI2cReadSda(void)
{
  return (HAL_GPIO_ReadPin(MAIN_IMU_I2C_SDA_PORT, MAIN_IMU_I2C_SDA_PIN) == GPIO_PIN_SET) ? 1U : 0U;
}

static void Main_ImuI2cPinsInit(void)
{
  GPIO_InitTypeDef GPIO_InitStruct = {0};

  __HAL_RCC_GPIOA_CLK_ENABLE();
  __HAL_RCC_GPIOB_CLK_ENABLE();
  __HAL_RCC_GPIOC_CLK_ENABLE();

  HAL_GPIO_WritePin(IMU_CS_GPIO_Port, IMU_CS_Pin, GPIO_PIN_SET);
  HAL_GPIO_WritePin(MAIN_IMU_I2C_SCL_PORT, MAIN_IMU_I2C_SCL_PIN, GPIO_PIN_SET);
  HAL_GPIO_WritePin(MAIN_IMU_I2C_SDA_PORT, MAIN_IMU_I2C_SDA_PIN, GPIO_PIN_SET);

  GPIO_InitStruct.Pin = IMU_CS_Pin;
  GPIO_InitStruct.Mode = GPIO_MODE_OUTPUT_PP;
  GPIO_InitStruct.Pull = GPIO_PULLUP;
  GPIO_InitStruct.Speed = GPIO_SPEED_FREQ_LOW;
  HAL_GPIO_Init(IMU_CS_GPIO_Port, &GPIO_InitStruct);

  GPIO_InitStruct.Pin = MAIN_IMU_I2C_SCL_PIN;
  GPIO_InitStruct.Mode = GPIO_MODE_OUTPUT_OD;
  GPIO_InitStruct.Pull = GPIO_PULLUP;
  GPIO_InitStruct.Speed = GPIO_SPEED_FREQ_LOW;
  HAL_GPIO_Init(MAIN_IMU_I2C_SCL_PORT, &GPIO_InitStruct);

  GPIO_InitStruct.Pin = MAIN_IMU_I2C_SDA_PIN;
  GPIO_InitStruct.Mode = GPIO_MODE_OUTPUT_OD;
  GPIO_InitStruct.Pull = GPIO_PULLUP;
  GPIO_InitStruct.Speed = GPIO_SPEED_FREQ_LOW;
  HAL_GPIO_Init(MAIN_IMU_I2C_SDA_PORT, &GPIO_InitStruct);

  Main_ImuI2cSetScl(1U);
  Main_ImuI2cSetSda(1U);
}

static void Main_ImuI2cStart(void)
{
  Main_ImuI2cSetSda(1U);
  Main_ImuI2cSetScl(1U);
  Main_ImuI2cDelay();
  Main_ImuI2cSetSda(0U);
  Main_ImuI2cDelay();
  Main_ImuI2cSetScl(0U);
  Main_ImuI2cDelay();
}

static void Main_ImuI2cStop(void)
{
  Main_ImuI2cSetSda(0U);
  Main_ImuI2cDelay();
  Main_ImuI2cSetScl(1U);
  Main_ImuI2cDelay();
  Main_ImuI2cSetSda(1U);
  Main_ImuI2cDelay();
}

static uint8_t Main_ImuI2cWriteByte(uint8_t value)
{
  for (uint8_t mask = 0x80U; mask != 0U; mask >>= 1U)
  {
    Main_ImuI2cSetSda((value & mask) != 0U ? 1U : 0U);
    Main_ImuI2cDelay();
    Main_ImuI2cSetScl(1U);
    Main_ImuI2cDelay();
    Main_ImuI2cSetScl(0U);
    Main_ImuI2cDelay();
  }

  Main_ImuI2cSetSda(1U);
  Main_ImuI2cDelay();
  Main_ImuI2cSetScl(1U);
  Main_ImuI2cDelay();
  uint8_t ack = (Main_ImuI2cReadSda() == 0U) ? 1U : 0U;
  Main_ImuI2cSetScl(0U);
  Main_ImuI2cDelay();
  return ack;
}

static uint8_t Main_ImuI2cReadByte(uint8_t ack)
{
  uint8_t value = 0U;

  Main_ImuI2cSetSda(1U);
  for (uint8_t i = 0U; i < 8U; ++i)
  {
    value <<= 1U;
    Main_ImuI2cDelay();
    Main_ImuI2cSetScl(1U);
    Main_ImuI2cDelay();
    value |= Main_ImuI2cReadSda();
    Main_ImuI2cSetScl(0U);
    Main_ImuI2cDelay();
  }

  Main_ImuI2cSetSda(ack != 0U ? 0U : 1U);
  Main_ImuI2cDelay();
  Main_ImuI2cSetScl(1U);
  Main_ImuI2cDelay();
  Main_ImuI2cSetScl(0U);
  Main_ImuI2cSetSda(1U);
  Main_ImuI2cDelay();

  return value;
}

static uint8_t Main_ImuI2cReadReg(uint8_t addr7, uint8_t reg, uint8_t *value)
{
  uint8_t ok = 1U;

  Main_ImuI2cStart();
  ok &= Main_ImuI2cWriteByte((uint8_t)(addr7 << 1U));
  ok &= Main_ImuI2cWriteByte(reg);
  Main_ImuI2cStart();
  ok &= Main_ImuI2cWriteByte((uint8_t)((addr7 << 1U) | 0x01U));
  *value = Main_ImuI2cReadByte(0U);
  Main_ImuI2cStop();

  return ok;
}

static void Main_ImuI2cProbeLoop(void)
{
  uint8_t id68 = 0U;
  uint8_t id69 = 0U;
  uint8_t ok68;
  uint8_t ok69;

  Main_ImuI2cPinsInit();
  HAL_Delay(350U);

  while (1)
  {
    ok68 = Main_ImuI2cReadReg(0x68U, 0x75U, &id68);
    HAL_Delay(2U);
    ok69 = Main_ImuI2cReadReg(0x69U, 0x75U, &id69);

    if ((ok68 != 0U && id68 == 0x47U) || (ok69 != 0U && id69 == 0x47U))
    {
      HAL_GPIO_TogglePin(LED1_GPIO_Port, LED1_Pin);
      HAL_Delay(80U);
    }
    else
    {
      HAL_GPIO_TogglePin(LED2_GPIO_Port, LED2_Pin);
      HAL_Delay(250U);
    }
  }
}
#endif

/* USER CODE END 0 */

int main(void)
{

  /* USER CODE BEGIN 1 */
  APP_Boot_TryRomDfu();

  /* USER CODE END 1 */

  /* MPU Configuration--------------------------------------------------------*/
  MPU_Config();

  /* Enable the CPU Cache */

  /* Enable I-Cache---------------------------------------------------------*/
  SCB_EnableICache();

  /* Enable D-Cache---------------------------------------------------------*/
  SCB_EnableDCache();

  /* MCU Configuration--------------------------------------------------------*/

  /* Reset of all peripherals, Initializes the Flash interface and the Systick. */
  HAL_Init();

  /* Configure the system clock */
  SystemClock_Config();

  /* USER CODE BEGIN SysInit */
  /* clock configured */

  /* USER CODE END SysInit */

  /* Initialize all configured peripherals */
  MX_GPIO_Init();
  MX_DMA_Init();
  MX_I2C1_Init();
  MX_I2C2_Init();
  MX_SDMMC1_SD_Init();
  MX_SPI1_Init();
  MX_SPI2_Init();
  MX_SPI3_Init();
  MX_TIM1_Init();
  MX_TIM4_Init();
  MX_TIM17_Init();
  MX_UART7_Init();
  MX_UART8_Init();
  MX_USART1_UART_Init();
  MX_USART2_UART_Init();
  MX_USART3_UART_Init();
  MX_USART6_UART_Init();
  MX_ADC1_Init();
  MX_UART4_Init();
  /* USER CODE BEGIN 2 */
  SVC_Timestamp_Init();
  Main_DebugUartPrint("BOOT user2_begin\r\n");
  Main_StagePulse(2U);
  BSP_UART_Release_USART1_ForExternalDebug();
  Main_DebugUartPrint("BOOT bsp_release_done\r\n");
  BSP_Init();
  Main_DebugUartPrint("BOOT bsp_init_done\r\n");
  Main_StagePulse(3U);
  APP_Init();
  Main_DebugUartPrint("BOOT app_init_done\r\n");
  Main_StagePulse(4U);
  /* USER CODE END 2 */

  /* Init scheduler */
  osKernelInitialize();  /* Call init function for freertos objects (in cmsis_os2.c) */
  MX_FREERTOS_Init();

  /* Start scheduler */
  osKernelStart();

  /* We should never get here as control is now taken by the scheduler */

  /* Infinite loop */
  while (1)
  {

  }
}

void SystemClock_Config(void)
{
  RCC_OscInitTypeDef RCC_OscInitStruct = {0};
  RCC_ClkInitTypeDef RCC_ClkInitStruct = {0};

  /** Supply configuration update enable
  */
  HAL_PWREx_ConfigSupply(PWR_LDO_SUPPLY);

  /** Configure the main internal regulator output voltage
  */
  __HAL_PWR_VOLTAGESCALING_CONFIG(PWR_REGULATOR_VOLTAGE_SCALE2);

  while(!__HAL_PWR_GET_FLAG(PWR_FLAG_VOSRDY)) {}

  /** Initializes the RCC Oscillators according to the specified parameters
  * in the RCC_OscInitTypeDef structure.
  */
  RCC_OscInitStruct.OscillatorType = RCC_OSCILLATORTYPE_HSE;
  RCC_OscInitStruct.HSEState = RCC_HSE_ON;
  RCC_OscInitStruct.PLL.PLLState = RCC_PLL_ON;
  RCC_OscInitStruct.PLL.PLLSource = RCC_PLLSOURCE_HSE;
  RCC_OscInitStruct.PLL.PLLM = 1;
  RCC_OscInitStruct.PLL.PLLN = 60;
  RCC_OscInitStruct.PLL.PLLP = 2;
  RCC_OscInitStruct.PLL.PLLQ = 4;
  RCC_OscInitStruct.PLL.PLLR = 2;
  RCC_OscInitStruct.PLL.PLLRGE = RCC_PLL1VCIRANGE_3;
  RCC_OscInitStruct.PLL.PLLVCOSEL = RCC_PLL1VCOWIDE;
  RCC_OscInitStruct.PLL.PLLFRACN = 0;
  if (HAL_RCC_OscConfig(&RCC_OscInitStruct) != HAL_OK)
  {
    Error_Handler();
  }

  /** Initializes the CPU, AHB and APB buses clocks
  */
  RCC_ClkInitStruct.ClockType = RCC_CLOCKTYPE_HCLK|RCC_CLOCKTYPE_SYSCLK
                              |RCC_CLOCKTYPE_PCLK1|RCC_CLOCKTYPE_PCLK2
                              |RCC_CLOCKTYPE_D3PCLK1|RCC_CLOCKTYPE_D1PCLK1;
  RCC_ClkInitStruct.SYSCLKSource = RCC_SYSCLKSOURCE_PLLCLK;
  RCC_ClkInitStruct.SYSCLKDivider = RCC_SYSCLK_DIV1;
  RCC_ClkInitStruct.AHBCLKDivider = RCC_HCLK_DIV2;
  RCC_ClkInitStruct.APB3CLKDivider = RCC_APB3_DIV1;
  RCC_ClkInitStruct.APB1CLKDivider = RCC_APB1_DIV2;
  RCC_ClkInitStruct.APB2CLKDivider = RCC_APB2_DIV2;
  RCC_ClkInitStruct.APB4CLKDivider = RCC_APB4_DIV2;

  if (HAL_RCC_ClockConfig(&RCC_ClkInitStruct, FLASH_LATENCY_2) != HAL_OK)
  {
    Error_Handler();
  }
}

 /* MPU Configuration */

void MPU_Config(void)
{
  MPU_Region_InitTypeDef MPU_InitStruct = {0};

  /* Disables the MPU */
  HAL_MPU_Disable();

  /** Initializes and configures the Region and the memory to be protected
  */
  MPU_InitStruct.Enable = MPU_REGION_ENABLE;
  MPU_InitStruct.Number = MPU_REGION_NUMBER0;
  MPU_InitStruct.BaseAddress = 0x0;
  MPU_InitStruct.Size = MPU_REGION_SIZE_4GB;
  MPU_InitStruct.SubRegionDisable = 0x87;
  MPU_InitStruct.TypeExtField = MPU_TEX_LEVEL0;
  MPU_InitStruct.AccessPermission = MPU_REGION_NO_ACCESS;
  MPU_InitStruct.DisableExec = MPU_INSTRUCTION_ACCESS_DISABLE;
  MPU_InitStruct.IsShareable = MPU_ACCESS_SHAREABLE;
  MPU_InitStruct.IsCacheable = MPU_ACCESS_NOT_CACHEABLE;
  MPU_InitStruct.IsBufferable = MPU_ACCESS_NOT_BUFFERABLE;

  HAL_MPU_ConfigRegion(&MPU_InitStruct);
  /* Enables the MPU */
  HAL_MPU_Enable(MPU_PRIVILEGED_DEFAULT);

}

void HAL_TIM_PeriodElapsedCallback(TIM_HandleTypeDef *htim)
{
  if (htim->Instance == TIM3)
  {
    HAL_IncTick();
  }
  /* USER CODE BEGIN Callback 1 */
  if (htim->Instance == TIM17) {
      SVC_Timestamp_Tick();
  }
  /* USER CODE END Callback 1 */
}

void Error_Handler(void)
{
  /* USER CODE BEGIN Error_Handler_Debug */
  /* User can add his own implementation to report the HAL error return state */
  /*
   * 开机没插 SD 卡：HAL_SD_Init 失败不是整机故障，记为无卡后返回继续开机，
   * 飞行日志降级为不记录（2026-09-25 实机：拔卡后整机卡死在这里，USB 都起不来）。
   * 其他任何地方出错仍照旧停机。
   */
  if (BSP_Board_SdInitFailed() != 0U)
  {
    return;
  }
  __disable_irq();
  while (1)
  {
  }
  /* USER CODE END Error_Handler_Debug */
}

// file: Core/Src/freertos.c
/* USER CODE BEGIN Header */
/**
  ******************************************************************************
  * File Name          : freertos.c
  * Description        : Code for freertos applications
  ******************************************************************************
  * @attention
  *
  * Copyright (c) 2026 STMicroelectronics.
  * All rights reserved.
  *
  * This software is licensed under terms that can be found in the LICENSE file
  * in the root directory of this software component.
  * If no LICENSE file comes with this software, it is provided AS-IS.
  *
  ******************************************************************************
  */
/* USER CODE END Header */

#include "FreeRTOS.h"
#include "task.h"
#include "main.h"
#include "FreeRTOS.h"
#include "cmsis_os2.h"

/* USER CODE BEGIN Includes */
/*
 * ============================================================================
 * 模块依赖说明
 * ============================================================================
 * App 层（应用逻辑）：
 *   app_diag.h       — 诊断记录（栈溢出 / malloc 失败时记录到 FLASH）
 *   app_sensor.h     — 传感器数据处理（零偏校准、坐标系对齐、低通滤波）
 *   app_messages.h   — 消息协议编解码（JSON / 二进制帧封装）
 *   app_tasks.h      — 各任务 Init/Step 函数声明
 *   app_telem_stream.h — 遥测流 v2（通道装配、掩码帧、双出口）
 *   app_elrs.h       — ELRS 遥控器链路（通道值读取）
 *
 * BSP 层（板级支持包——硬件抽象）：
 *   bsp_baro.h       — 气压计 SPL06-007 驱动
 *   bsp_imu.h        — IMU (ICM-42688-P) 驱动
 *   bsp_pwm.h        — TIM2 PWM 输出（CH1/2 电调，CH3/4 普通舵机）
 *   bsp_aiwb2_power.h — Ai-WB2 WiFi 模块电源控制
 *
 * Driver 层（外设驱动——算法 / 协议）：
 *   drv_coax_ctrl.h  — 同轴倾转旋翼控制器（论文控制分配）
 */
#include "app_diag.h"
#include "app_flight_log.h"
#include "app_imu_capture.h"
#include "app_imu_health.h"
#include "app_led.h"
#include "app_nav_estimator.h"
#include "app_sensor.h"
#include "app_messages.h"
#include "app_tasks.h"
#include "app_telemetry.h"
#include "app_ident.h"
#include "app_servo_cal.h"
#include "app_servo_jog.h"
#include "app_servo_feedback.h"
#include "app_servo_feedback_bench.h"
#include "app_stabilizer.h"
#include <math.h>
#include <string.h>

#include "app_telem_stream.h"
#include "app_elrs.h"
#include "app_optical_flow.h"
#include "bsp_baro.h"
#include "bsp_imu.h"
#include "bsp_bus_servo.h"
#include "bsp_pwm.h"
#include "bsp_aiwb2_power.h"
#include "drv_attitude_fusion.h"
#include "drv_coax_ctrl.h"
#include "drv_nav_ekf.h"

/* USER CODE END Includes */

/* USER CODE BEGIN PD */
/*
 * ============================================================================
 * 传感器相关常量
 * ============================================================================
 * IMU 数据就绪优先由 PC0 外部中断触发，中断中设置 Thread Flag。
 * 若短时间未等到中断，只读取一次 IMU ready 状态作为兜底；坏帧/短暂丢帧会被跳过。
 */
#define SENSOR_IMU_DATA_READY_FLAG     0x0001U  /* 位 0：IMU 数据就绪事件标志          */
#define SENSOR_IMU_DRDY_TIMEOUT_MS     20U      /* 单次等待 DRDY 的超时时间            */
#define SENSOR_IMU_DRDY_MISS_FAULT_LIMIT 50U    /* 连续 1s 无 DRDY/ready 才锁存故障    */
#define SENSOR_IMU_READ_FAIL_LIMIT     25U      /* 连续读失败次数，超过后锁存故障      */
#define SENSOR_MAG_PERIOD_US           50000ULL /* 磁力计步进间隔 50ms = 20Hz          */
/* 稳定器/导航/舵机常量已移至 App/Src/app_stabilizer.c */
/* 遥测帧的周期、长度、通道装配已移至 App/Src/app_telem_stream.c + app_telem_port.c */
/* USER CODE END PD */

/* USER CODE BEGIN Variables */
/*
 * ============================================================================
 * 全局同步对象
 * ============================================================================
 * imuDataReadySemaphore — IMU 数据就绪信号量
 *   生产者：Sensor_Task（每次 IMU 采样完成后 release）
 *   消费者：StabilizerTask（acquire 后开始消费 SensorSampleQueue）
 *   初始值 0，最大值 1（二进制信号量，只做事件通知不做计数）
 *
 * 遥测流开关 vofaStreamActive 已移至 App/Src/app_telem_stream.c。
 */
osSemaphoreId_t imuDataReadySemaphore;

/* USER CODE END Variables */
/* Definitions for Stabilizer */
osThreadId_t StabilizerHandle;
const osThreadAttr_t Stabilizer_attributes = {
  .name = "Stabilizer",
  .stack_size = 2048 * 4,
  .priority = (osPriority_t) osPriorityNormal,
};
/* Definitions for SensorTask */
osThreadId_t SensorTaskHandle;
const osThreadAttr_t SensorTask_attributes = {
  .name = "SensorTask",
  .stack_size = 512 * 4,
  .priority = (osPriority_t) osPriorityNormal,
};
/* Definitions for messageTask */
osThreadId_t messageTaskHandle;
const osThreadAttr_t messageTask_attributes = {
  .name = "messageTask",
  .stack_size = 1024 * 4,
  .priority = (osPriority_t) osPriorityBelowNormal,
};
/* Definitions for UARTTask */
osThreadId_t UARTTaskHandle;
const osThreadAttr_t UARTTask_attributes = {
  .name = "UARTTask",
  .stack_size = 1024 * 4,
  .priority = (osPriority_t) osPriorityNormal,
};
/* Definitions for backgroundTask */
osThreadId_t backgroundTaskHandle;
const osThreadAttr_t backgroundTask_attributes = {
  .name = "backgroundTask",
  .stack_size = 1024 * 4,
  .priority = (osPriority_t) osPriorityBelowNormal,
};
/* Definitions for VOFA_Task */
osThreadId_t VOFA_TaskHandle;
const osThreadAttr_t VOFA_Task_attributes = {
  .name = "VOFA_Task",
  .stack_size = 512 * 4,
  .priority = (osPriority_t) osPriorityBelowNormal,
};
/* Definitions for uartTxQueue */
osMessageQueueId_t uartTxQueueHandle;
const osMessageQueueAttr_t uartTxQueue_attributes = {
  .name = "uartTxQueue"
};
/* Definitions for SensorSampleQueue */
osMessageQueueId_t SensorSampleQueueHandle;
const osMessageQueueAttr_t SensorSampleQueue_attributes = {
  .name = "SensorSampleQueue"
};
/* Definitions for backgroundReqQueue */
osMessageQueueId_t backgroundReqQueueHandle;
const osMessageQueueAttr_t backgroundReqQueue_attributes = {
  .name = "backgroundReqQueue"
};
/* Definitions for backgroundRespQueue */
osMessageQueueId_t backgroundRespQueueHandle;
const osMessageQueueAttr_t backgroundRespQueue_attributes = {
  .name = "backgroundRespQueue"
};
/* Definitions for vofaLogQueue */
osMessageQueueId_t vofaLogQueueHandle;
const osMessageQueueAttr_t vofaLogQueue_attributes = {
  .name = "vofaLogQueue"
};
/* Definitions for flashBusMutex */
osMutexId_t flashBusMutexHandle;
const osMutexAttr_t flashBusMutex_attributes = {
  .name = "flashBusMutex",
  .attr_bits = osMutexRecursive,
};

void StabilizerTask(void *argument);
void Sensor_Task(void *argument);
void message_push(void *argument);
void UART_fun(void *argument);
void BackgroundTask(void *argument);
void VOFA_task(void *argument);

extern void MX_USB_DEVICE_Init(void);
void MX_FREERTOS_Init(void); /* (MISRA C 2004 rule 8.1) */

/* Hook prototypes */
void vApplicationStackOverflowHook(xTaskHandle xTask, char *pcTaskName);
void vApplicationMallocFailedHook(void);

/* USER CODE BEGIN 4 */
/*
 * vApplicationStackOverflowHook — 任务栈溢出钩子
 *
 * 触发条件：configCHECK_FOR_STACK_OVERFLOW 设置为 1 或 2 时，
 * FreeRTOS 在每个任务切换时检查栈指针是否越界。
 *
 * 处理策略：
 *   1. 记录栈溢出事件到诊断系统（APP_Diag_RecordStackOverflow）
 *   2. 关全局中断（taskDISABLE_INTERRUPTS）
 *   3. 死循环——栈溢出是不可恢复的错误，继续运行会导致内存损坏
 *
 * 排查方法：如果某个任务反复触发此钩子，增大该任务的 .stack_size，
 * 或检查函数内的局部变量是否过大（大数组应改为 static）。
 */
void vApplicationStackOverflowHook(xTaskHandle xTask, char *pcTaskName)
{
   (void)xTask;
   APP_Diag_RecordStackOverflow(pcTaskName);
   taskDISABLE_INTERRUPTS();
   for(;;)
   {
   }
}
/* USER CODE END 4 */

/* USER CODE BEGIN 5 */
/*
 * vApplicationMallocFailedHook — 动态内存分配失败钩子
 *
 * 触发条件：configUSE_MALLOC_FAILED_HOOK = 1 时，
 * pvPortMalloc() 返回 NULL（堆内存耗尽）时调用。
 *
 * FreeRTOS 内部在创建任务/队列/信号量/定时器时都会调用 pvPortMalloc()。
 * 堆大小由 FreeRTOSConfig.h 中的 configTOTAL_HEAP_SIZE 定义。
 *
 * 处理策略：与栈溢出相同——记录诊断信息后死循环。
 *
 * 排查方法：检查 configTOTAL_HEAP_SIZE 是否足够；
 * 检查是否有内存泄漏（创建对象后未删除）；
 * 使用 xPortGetFreeHeapSize() 监控剩余堆空间。
 */
void vApplicationMallocFailedHook(void)
{
   APP_Diag_RecordMallocFailed();
   taskDISABLE_INTERRUPTS();
   for(;;)
   {
   }
}
/* USER CODE END 5 */

void MX_FREERTOS_Init(void) {

  /* Create the recursive mutex(es) */
  /* creation of flashBusMutex */
  flashBusMutexHandle = osMutexNew(&flashBusMutex_attributes);

  /* USER CODE BEGIN RTOS_SEMAPHORES */
  /* 创建 IMU 数据就绪信号量：初始 0，最大 1，二进制事件通知 */
  imuDataReadySemaphore = osSemaphoreNew(1U, 0U, NULL);
  /* USER CODE END RTOS_SEMAPHORES */

  /* Create the queue(s) */
  /* creation of uartTxQueue */
  uartTxQueueHandle = osMessageQueueNew (32, sizeof(APP_UART_TxMessage), &uartTxQueue_attributes);

  /* creation of SensorSampleQueue */
  SensorSampleQueueHandle = osMessageQueueNew (8, sizeof(APP_Sensor_SampleMessage), &SensorSampleQueue_attributes);

  /* creation of backgroundReqQueue */
  backgroundReqQueueHandle = osMessageQueueNew (8, sizeof(APP_BackgroundRequest), &backgroundReqQueue_attributes);

  /* creation of backgroundRespQueue */
  backgroundRespQueueHandle = osMessageQueueNew (8, sizeof(APP_BackgroundResponse), &backgroundRespQueue_attributes);

  /* creation of vofaLogQueue */
  vofaLogQueueHandle = osMessageQueueNew (1, sizeof(APP_Sensor_SampleMessage), &vofaLogQueue_attributes);

  /* USER CODE BEGIN RTOS_QUEUES */
  /* add queues, ... */
  APP_Task_LED_Init();
  APP_ServoCal_Init();
  APP_ServoJog_Init();
  /* USER CODE END RTOS_QUEUES */

  /* Create the thread(s) */
  /* creation of Stabilizer */
  StabilizerHandle = osThreadNew(StabilizerTask, NULL, &Stabilizer_attributes);

  /* creation of SensorTask */
  SensorTaskHandle = osThreadNew(Sensor_Task, NULL, &SensorTask_attributes);

  /* creation of messageTask */
  messageTaskHandle = osThreadNew(message_push, NULL, &messageTask_attributes);

  /* creation of UARTTask */
  UARTTaskHandle = osThreadNew(UART_fun, NULL, &UARTTask_attributes);

  /* creation of backgroundTask */
  backgroundTaskHandle = osThreadNew(BackgroundTask, NULL, &backgroundTask_attributes);

  /* creation of VOFA_Task */
  VOFA_TaskHandle = osThreadNew(VOFA_task, NULL, &VOFA_Task_attributes);

  /* USER CODE BEGIN RTOS_THREADS */
  /* add threads, ... */
  APP_Task_LED_Start();   /* 状态灯 1 kHz 软件调光，线程体在 App/Src/app_tasks.c */
  /* USER CODE END RTOS_THREADS */

}

/* USER CODE BEGIN Header_StabilizerTask */
/**
  * @brief  StabilizerTask —— 姿态融合 + 控制输出（核心控制线程）
  * @param  argument: Not used
  * @retval None
  *
  * 这是整个飞控的核心任务，负责：
  *   1. 等待 IMU 数据就绪（通过 imuDataReadySemaphore 信号量）
  *   2. 从 SensorSampleQueue 消费传感器数据
  *   3. x-io Fusion AHRS → roll / pitch / yaw
  *   4. 将融合后的姿态写入 vofaLogQueue（VOFA_task 在上位机显示）
  *   5. 按 25Hz 控制周期输出舵机指令
  *
  * 数据流：
  *   Sensor_Task → SensorSampleQueue → 这里
  *     ① Fusion 四元数传播、动态加速度拒绝和自动恢复
  *     ② 写入 vofaLogQueue（VOFA_task 50Hz 发送到上位机）
  *     ③ 控制器更新（500Hz，舵机总线仅在目标变化时发送）
  *
  * 舵机控制有两种模式（编译期切换）：
  *   模式 A (USE_DIRECT_ANGLE_SERVO=1)：姿态角直接映射为舵机脉宽
  *   模式 B (USE_DIRECT_ANGLE_SERVO=0)：经过 Simulink 生成的同轴控制器
  *
  * 注意：未满足安全条件时断开电调 PWM 输出（CCR=0）。
  */
/* USER CODE END Header_StabilizerTask */
void StabilizerTask(void *argument)
{
  /* init code for USB_DEVICE */
  MX_USB_DEVICE_Init();
  /* USER CODE BEGIN StabilizerTask */

  /* 核心控制逻辑已拆到独立模块 App/Src/app_stabilizer.c */
  APP_Stabilizer_Run(imuDataReadySemaphore, SensorSampleQueueHandle,
                     vofaLogQueueHandle);

  /* USER CODE END StabilizerTask */
}

/* USER CODE BEGIN Header_Sensor_Task */
/**
  * @brief  Sensor_Task —— IMU 传感器采集与数据预处理（1kHz，中断驱动）
  * @param  argument: Not used
  * @retval None
  *
  * 这是整个飞控的数据源头，负责：
  *   1. 初始化 IMU（ICM-42688-P）、气压计（SPL06-007）、磁力计（QMC5883L）
  *   2. 等待 PC0 外部中断通知（IMU 数据就绪），超时后轮询兜底
  *   3. 读取 IMU 原始寄存器值 → 转换为物理单位（dps / g）
  *   4. 陀螺仪零偏校准（前 1000 个样本自动均值，要求静止）
  *   5. 坐标系对齐（ICM 芯片坐标系 → 机体 NED 坐标系）
  *   6. 低通滤波（陀螺 80Hz、加速度 30Hz，IIR 一阶）
  *   7. 气压计降采样读取（1kHz 中每 32 次读一次 ≈ 32Hz）
  *   8. 组装 SensorSampleMessage → 推入 SensorSampleQueue
  *   9. Release imuDataReadySemaphore 通知 StabilizerTask 消费
  *
  * 运行时序：
  *   硬件 IRQ ──→ Thread Flag ──→ 本任务唤醒 ──→ SPI 读取 ──→ 处理流水线
  *   ──→ 推送队列 ──→ Release 信号量 ──→ 再次阻塞等待 Thread Flag
  *
  * 涉及的硬件接口：
  *   SPI1 → ICM-42688-P (IMU, 加速度 + 陀螺仪)
  *   I2C1 → SPL06-007   (气压计)
  *   I2C1 → QMC5883L    (磁力计)
  *   PC0  → EXTI 中断   (IMU INT1 数据就绪引脚)
  */
/* USER CODE END Header_Sensor_Task */
void Sensor_Task(void *argument)
{
  /* USER CODE BEGIN Sensor_Task */
  BSP_IMU_Invalidate();                  /* 复位 IMU 驱动内部状态              */
  APP_ImuHealth_Init();                  /* 采样链健康监测（DRDY 静默降级检测） */

  /* APP_Task_GPS_Init();  暂时停止 GPS */
  APP_Task_OpticalFlow_Init();
  APP_Task_MAG_Init();                   /* 初始化磁力计 QMC5883L              */

  /* ---- 初始化 IMU（重试直到成功） ---- */
  while (BSP_IMU_Init() != DRV_IMU_OK) {
    osDelay(50);
  }
  BSP_BARO_Init();   /* 气压计初始化，失败时在读数据时重试 */

  DRV_IMU_RawData    raw;               /* IMU 原始 ADC 值（寄存器原始读数）    */
  DRV_IMU_ScaledData scaled;            /* IMU 物理单位值（dps / g）            */
  uint32_t sample_count = 0U;           /* 总采样帧计数（溢出回绕是安全的）     */
  uint32_t baro_cnt     = 0U;           /* 气压计降采样计数器（32 分频）        */
  uint64_t last_mag_step_us = 0ULL;     /* 磁力计上次步进时间 [μs]              */
  float    baro_pa      = 0.0f;         /* 当前气压值 [Pa]，保持旧值直到更新    */
  float    baro_temp    = 0.0f;         /* 当前气压计温度 [°C]                  */

  /* 陀螺仪零偏校准状态 */
  APP_Sensor_GyroBias gyro_bias = {0};
  APP_Sensor_RateMeter imu_rate_meter = {0}; /* IMU 实际采样率统计              */
  APP_Sensor_RateMeter imu_irq_rate_meter = {0};
  APP_Sensor_RateMeter imu_poll_rate_meter = {0};

  /*
   * 低通滤波器：二阶 Butterworth，陀螺 80Hz，加速度 40Hz，dt = 0.001s。
   *
   * 截止频率由实测定速扫描确定（data/captures/imu_vibration/）：桨叶通过频率
   * 随油门从 56Hz 线性升到悬停的 180Hz（r=0.996，确认是真实振动非混叠）。
   * 80Hz 二阶在 180Hz 给 -15.9dB，原一阶只有 -8.9dB；代价是 10Hz 处群延迟
   * 从 1.93ms 增到 2.80ms，对姿态环可接受。
   *
   * 加速度抬到 40Hz（原 30Hz）：二阶滚降已足够陡，不必再靠压低截止频率换
   * 衰减，抬高可减少重力方向的相位滞后。
   */
  APP_Sensor_Lpf gyro_lpf[3], acc_lpf[3];
  uint32_t imu_irq_ready_count = 0U;
  uint32_t imu_poll_ready_count = 0U;
  uint32_t imu_read_fail_count = 0U;
  uint32_t imu_drdy_miss_count = 0U;
  for (uint32_t i = 0U; i < 3U; i++) {
    APP_Sensor_LpfInit(&gyro_lpf[i], 80.0f, 0.001f);
    APP_Sensor_LpfInit(&acc_lpf[i], 40.0f, 0.001f);
  }

  osDelay(10);

  for(;;)
  {
    uint64_t imu_sample_timestamp_us = APP_SENSOR_TIMESTAMP_INVALID;
    uint32_t imu_ready_flags;

    /*
     * 步骤 1：等待 IMU 数据就绪
     * PC0 EXTI → HAL_GPIO_EXTI_Callback → osThreadFlagsSet → 本任务被唤醒。
     * 未等到中断时只读一次 ready 状态；若仍未 ready，则跳过本轮继续等下一帧。
     */
    imu_ready_flags =
      osThreadFlagsWait(SENSOR_IMU_DATA_READY_FLAG, osFlagsWaitAny,
                        SENSOR_IMU_DRDY_TIMEOUT_MS);
    if ((imu_ready_flags & SENSOR_IMU_DATA_READY_FLAG) != 0U) {
      imu_irq_ready_count++;
      imu_drdy_miss_count = 0U;
      APP_ImuHealth_NoteSample(1U);
      if (APP_IMU_ReadDataReadyTimestamp(&imu_sample_timestamp_us) == 0U) {
        imu_sample_timestamp_us = SVC_Timestamp_Us();
      }
    } else {
      bool imu_ready = false;

      if ((BSP_IMU_IsDataReady(&imu_ready) == DRV_IMU_OK) && imu_ready) {
        imu_poll_ready_count++;
        /*
         * 这里刻意不再清零 imu_drdy_miss_count：轮询兜底成功只说明"拿到了
         * 数据"，不说明"中断是健康的"。以前两者混为一谈，导致 DRDY 永久失效时
         * 兜底每 20ms 成功一次、miss 计数被反复清零，故障门永远不触发，整条链
         * 静默降到 50Hz。miss 计数现在只在真正收到中断时清零。
         */
        imu_drdy_miss_count++;
        APP_ImuHealth_NoteSample(0U);
        imu_sample_timestamp_us = SVC_Timestamp_Us();
        if (imu_drdy_miss_count >= SENSOR_IMU_DRDY_MISS_FAULT_LIMIT) {
          APP_Stabilizer_LatchImuFault(STABILIZER_IMU_FAULT_DRDY_TIMEOUT);
        }
      } else {
        imu_drdy_miss_count++;
        if (imu_drdy_miss_count >= SENSOR_IMU_DRDY_MISS_FAULT_LIMIT) {
          APP_Stabilizer_LatchImuFault(STABILIZER_IMU_FAULT_DRDY_TIMEOUT);
          (void)osSemaphoreRelease(imuDataReadySemaphore);
        }
        continue;
      }
    }

    /* ---- 步骤 2：SPI 读取 IMU 原始值，转换为物理单位 ---- */
    if (BSP_IMU_ReadRaw(&raw) != DRV_IMU_OK) {
      imu_read_fail_count++;
      if (imu_read_fail_count >= SENSOR_IMU_READ_FAIL_LIMIT) {
        APP_Stabilizer_LatchImuFault(STABILIZER_IMU_FAULT_READ_FAIL);
        (void)osSemaphoreRelease(imuDataReadySemaphore);
      }
      continue;
    }
    imu_read_fail_count = 0U;
    /*
     * 只有中断链健康（本帧由 DRDY 唤醒）时才清除故障锁存。以前无条件清除，
     * 于是上一行刚锁存的 DRDY_TIMEOUT 会被下一帧立刻抹掉，故障标志形同虚设。
     */
    if (imu_drdy_miss_count == 0U) {
      APP_Stabilizer_ClearImuFault();
    }
    APP_Stabilizer_MarkImuSample(HAL_GetTick());
    APP_ImuHealth_Update(HAL_GetTick());

    sample_count++;

    /*
     * 振动谱采集钩子：必须放在缩放/对齐/低通之前。
     * 飞行日志和 VOFA 都是抽取后且已滤波的数据，看不到 150~300 Hz 的桨叶带，
     * 无法用来确定 AAF 和 IIR 的截止频率；这里取的是未经处理的原始 LSB。
     * 未启动采集时该调用直接返回，不会阻塞 1kHz 采样节奏。
     */
    APP_IMU_Capture_Push((uint32_t)imu_sample_timestamp_us,
                         &raw,
                         BSP_PWM_GetEscPulse(1),
                         BSP_PWM_GetEscPulse(2));

    APP_IMU_RawToScaled(&raw, &scaled);  /* ADC → 物理单位（dps / g）         */

    /*
     * 步骤 3：陀螺仪零偏校准
     * APP_Sensor_CalibrateGyroBias() 内部累积前 1000 个样本求均值。
     * 校准完成后（gyro_bias.ready == true），后续所有采样都减去零偏。
     * 重要：校准时飞行器必须完全静止，否则零偏不准确。
     */
    {
      float g[3] = {scaled.gyro_x_dps, scaled.gyro_y_dps, scaled.gyro_z_dps};
      if (APP_Sensor_TakeGyroRecalRequest() != 0U) {
        /* IMUZERO：台架上重启时舵机一动机体就绕杆摆，摆动会被当成零偏；静下来后重新采样。 */
        gyro_bias = (APP_Sensor_GyroBias){0};
      }
      if (APP_Sensor_CalibrateGyroBias(g[0], g[1], g[2], &gyro_bias)) {
        /* 校准刚完成，第一次减零偏自然生效 */
      }
      if (gyro_bias.ready) {
        g[0] -= gyro_bias.bias[0];
        g[1] -= gyro_bias.bias[1];
        g[2] -= gyro_bias.bias[2];
      }
      scaled.gyro_x_dps = g[0];
      scaled.gyro_y_dps = g[1];
      scaled.gyro_z_dps = g[2];
    }

    /*
     * 步骤 4：坐标系对齐 + 低通滤波
     * ICM-42688-P 芯片坐标系与机体坐标系不一定一致（取决于 PCB 焊接方向）。
     * APP_Sensor_AlignToAirframe() 通过轴重排和取反将传感器轴映射到机体轴。
     * 机体坐标系定义（NED 约定）：
     *   X → 机头前方,  Y → 机身右侧,  Z → 机身下方
     * 对齐后分别对陀螺和加速度施加一阶 IIR 低通滤波。
     */
    {
      float a[3] = {scaled.accel_x_g, scaled.accel_y_g, scaled.accel_z_g};
      float g[3] = {scaled.gyro_x_dps, scaled.gyro_y_dps, scaled.gyro_z_dps};
      float a_align[3], g_align[3];

      APP_Sensor_AlignToAirframe(a, a_align);
      APP_Sensor_AlignToAirframe(g, g_align);
      APP_Sensor_LpfApply3f(gyro_lpf, g_align, g_align); /* IIR 低通：陀螺    */
      APP_Sensor_LpfApply3f(acc_lpf,  a_align, a_align); /* IIR 低通：加速度  */

      /* 记录滤波后的值，使 IIR 的实际衰减可以和同一帧的输入直接对比。 */
      APP_IMU_Capture_AnnotateFiltered(a_align, g_align, gyro_bias.ready);

      scaled.accel_x_g  = a_align[0];  scaled.accel_y_g = a_align[1];  scaled.accel_z_g = a_align[2];
      scaled.gyro_x_dps = g_align[0];  scaled.gyro_y_dps = g_align[1]; scaled.gyro_z_dps = g_align[2];
    }

    /*
     * 步骤 5：气压计降采样读取（≈32Hz）
     * 气压计不需要 1kHz 更新——大气压力变化缓慢（< 10Hz）。
     * 每 32 次 IMU 循环（= 32ms @ 1kHz）读取一次，实际频率 ≈ 31.25Hz。
     * SPI06-007 偶有上电复位后无响应的问题——读取失败时重新初始化。
     */
    uint8_t baro_fresh = 0U;

    if (++baro_cnt >= 32U) {
      baro_cnt = 0U;
      uint8_t buf[6];                    /* 3 字节压力原始值 + 3 字节温度原始值 */

      if (BSP_BARO_ReadRawRegisters(0x00U, buf, 6U) == DRV_BARO_OK) {
        /* SPL06-007：24 位补码，MSB 在前，左移后算术右移完成符号扩展 */
        int32_t prs_raw = ((int32_t)(((uint32_t)buf[0] << 24) | ((uint32_t)buf[1] << 16) | ((uint32_t)buf[2] << 8))) >> 8;
        int32_t tmp_raw = ((int32_t)(((uint32_t)buf[3] << 24) | ((uint32_t)buf[4] << 16) | ((uint32_t)buf[5] << 8))) >> 8;

        APP_IMU_ConvertBaro(prs_raw, tmp_raw, &baro_pa, &baro_temp);
        baro_fresh = 1U;
      } else {
        /* 读取失败：复位驱动状态 + 重新初始化传感器 */
        BSP_BARO_Invalidate();
        BSP_BARO_Init();
      }
    }

    /*
     * 步骤 6：组装传感器消息 → 推送队列 → 通知 StabilizerTask
     * SensorSampleMessage 包含：
     *   - 时间戳（SVC_Timestamp_Us：32 位微秒硬件计数器）
     *   - IMU 数据（加速度 + 陀螺仪，已滤波 + 坐标对齐 + 零偏校正）
     *   - 气压计数据（压力 + 温度，baro_updated 标志是否本帧新鲜）
     *   - IMU 采样率统计
     *
     * 队列满处理：丢弃最旧的一帧再写入（覆盖模式），保证 Stabilizer 拿到最新数据。
     *
     * 顺序关键：必须先 Push 队列，再 Release 信号量！
     * 否则 StabilizerTask 被唤醒后发现队列空，白跑一趟。
     */
    APP_Sensor_SampleMessage msg;

    msg.base.timestamp_us    = imu_sample_timestamp_us;
    msg.base.type            = APP_SENSOR_TYPE_IMU;
    msg.base.sequence        = sample_count;
    msg.raw_imu              = raw;
    msg.imu                  = scaled;
    msg.roll_deg             = 0.0f;   /* Stabilizer 填入 */
    msg.pitch_deg            = 0.0f;
    msg.yaw_deg              = 0.0f;
    msg.baro_updated         = baro_fresh;
    msg.baro_pressure_pa     = baro_pa;
    msg.baro_temperature_c   = baro_temp;
    msg.imu_sample_rate_hz   = APP_SensorRateMeter_Update(&imu_rate_meter,
                                                          msg.base.timestamp_us,
                                                          sample_count);
    msg.imu_irq_sample_rate_hz  = APP_SensorRateMeter_Update(&imu_irq_rate_meter,
                                                              msg.base.timestamp_us,
                                                              imu_irq_ready_count);
    msg.imu_poll_sample_rate_hz = APP_SensorRateMeter_Update(&imu_poll_rate_meter,
                                                              msg.base.timestamp_us,
                                                              imu_poll_ready_count);
    msg.imu_age_ms = 0.0f;
    memset(&msg.attitude_debug, 0, sizeof(msg.attitude_debug));
    msg.gyro_bias_ready = gyro_bias.ready;
    msg.imu_data_ready_count = imu_irq_ready_count;
    msg.imu_poll_ready_count = imu_poll_ready_count;
    msg.fusion_acceleration_error_deg = 0.0f;
    msg.fusion_acceleration_recovery_trigger = 0.0f;
    msg.fusion_accel_correction_count = 0U;
    msg.fusion_accelerometer_ignored = 0U;
    msg.fusion_acceleration_recovery = 0U;
    msg.fusion_angular_rate_recovery = 0U;
    msg.fusion_accel_norm_rejected = 0U;

    if (osMessageQueuePut(SensorSampleQueueHandle, &msg, 0U, 0U) != osOK) {
      APP_Sensor_SampleMessage drop;
      (void)osMessageQueueGet(SensorSampleQueueHandle, &drop, 0U, 0U);
      (void)osMessageQueuePut(SensorSampleQueueHandle, &msg, 0U, 0U);
    }

    /* 步骤 7：Release 信号量 → 唤醒 StabilizerTask */
    (void)osSemaphoreRelease(imuDataReadySemaphore);

    /*
     * 步骤 8：磁力计步进（非阻塞，20Hz 独立节奏）
     * 磁力计挂在 I2C 总线上，读取速度慢（~100Hz max），且数据不需要 1kHz 更新。
     * 使用独立的时间间隔 SENSOR_MAG_PERIOD_US (50ms = 20Hz) 来控制步进。
     */
                             /* APP_Task_GPS_Step();  暂时停止 GPS */
    APP_Task_OpticalFlow_Step();
    {
      uint64_t now_us = msg.base.timestamp_us;

      if ((last_mag_step_us == 0ULL) ||
          ((now_us - last_mag_step_us) >= SENSOR_MAG_PERIOD_US)) {
        last_mag_step_us = now_us;
        APP_Task_MAG_Step();
      }
    }
  }
  /* USER CODE END Sensor_Task */
}

/* USER CODE BEGIN Header_message_push */
/**
  * @brief  messageTask —— 消息协议处理（JSON 解析 / 二进制帧编解码）
  * @param  argument: Not used
  * @retval None
  *
  * 功能：
  *   处理来自上位机 / 遥控器的消息协议，包括：
  *   - JSON 消息解析与应答
  *   - 二进制帧封包 / 解包
  *   - 参数读写请求的协议层处理
  *   - WiFi 模块（Ai-WB2）的命令交互
  *
  * 优先级 BelowNormal：消息处理不影响飞控实时性。
  * 栈 1024×4：JSON 处理和字符串操作需要较大栈空间。
  */
/* USER CODE END Header_message_push */
void message_push(void *argument)
{
  /* USER CODE BEGIN message_push */
  APP_Task_Message_Init();
  /* Infinite loop */
  for(;;)
  {
    APP_Task_Message_Step();
  }
  /* USER CODE END message_push */
}

/* USER CODE BEGIN Header_UART_fun */
/**
  * @brief  UARTTask —— UART 收发调度
  * @param  argument: Not used
  * @retval None
  *
  * 功能：
  *   统一管理所有 UART 外设的数据收发：
  *   - UART4 (PD.1) → 舵机总线（半双工串行舵机协议）
  *   - UART7 → ELRS 遥控器接收机（Crossfire 协议）
  *   - UART8 → Ai-WB2 WiFi 模块（AT 命令 + 数据透传）
  *
  * 从 uartTxQueue 中取出待发送数据，分别投递到对应的 UART 外设。
  * 各 UART 的接收在中断（IDLE / RXNE）中完成，此任务做分发调度。
  *
  * 优先级 Normal：UART 发送不及时会导致舵机丢帧或 WiFi 阻塞。
  * 栈 1024×4：三个 UART 通道的缓冲区和协议栈需要较大空间。
  */
/* USER CODE END Header_UART_fun */
void UART_fun(void *argument)
{
  /* USER CODE BEGIN UART_fun */
  APP_Task_UART_Init();
  /* Infinite loop */
  for(;;)
  {
    APP_Task_UART_Step();
  }
  /* USER CODE END UART_fun */
}

/* USER CODE BEGIN Header_BackgroundTask */
/**
  * @brief  BackgroundTask —— 后台低优先级任务（FLASH 参数管理）
  * @param  argument: Not used
  * @retval None
  *
  * 功能：
  *   执行不应该阻塞控制环（SensorTask / StabilizerTask）的慢操作：
  *   - 参数从 FLASH 自动加载（上电后首次运行）
  *   - 参数异步保存（修改参数后延迟写入 FLASH，减少擦写次数）
  *   - 维护模式 FLASH 块读写（坏块管理、磨损均衡等）
  *
  * 交互方式：请求-响应模式
  *   - 请求者（任意任务）→ backgroundReqQueue → 本任务处理
  *   - 本任务 → backgroundRespQueue → 请求者取走结果
  *
  * 所有 FLASH 操作前必须获取 flashBusMutex（递归互斥锁）。
  *
  * 优先级 BelowNormal：只在所有实时任务空闲时执行。
  * 栈 1024×4：FLASH 页缓冲需要较大栈空间（一页 = 128 字节，需双缓冲）。
  */
/* USER CODE END Header_BackgroundTask */
void BackgroundTask(void *argument)
{
  /* USER CODE BEGIN BackgroundTask */
  APP_Task_Background_Init();
  /* Infinite loop */
  for(;;)
  {
    APP_Task_Background_Step();
  }
  /* USER CODE END BackgroundTask */
}

/* USER CODE BEGIN Header_VOFA_task */
/**
  * @brief  VOFA_Task —— 遥测流发送任务
  * @param  argument: Not used
  * @retval None
  *
  * 任务体整体位于 App/Src/app_telem_stream.c（策略）与 app_telem_port.c
  * （平台实现）。这里只剩调用：通道装配、掩码帧编码、出口选择、导出互斥
  * 都不再写在 CubeMX 生成的文件里。
  *
  * 优先级 Low：可视化数据允许延迟或丢帧，不影响飞行安全。
  */
/* USER CODE END Header_VOFA_task */
void VOFA_task(void *argument)
{
  /* USER CODE BEGIN VOFA_task */
  for(;;)
  {
    APP_TelemStream_Tick();
  }
  /* USER CODE END VOFA_task */
}
